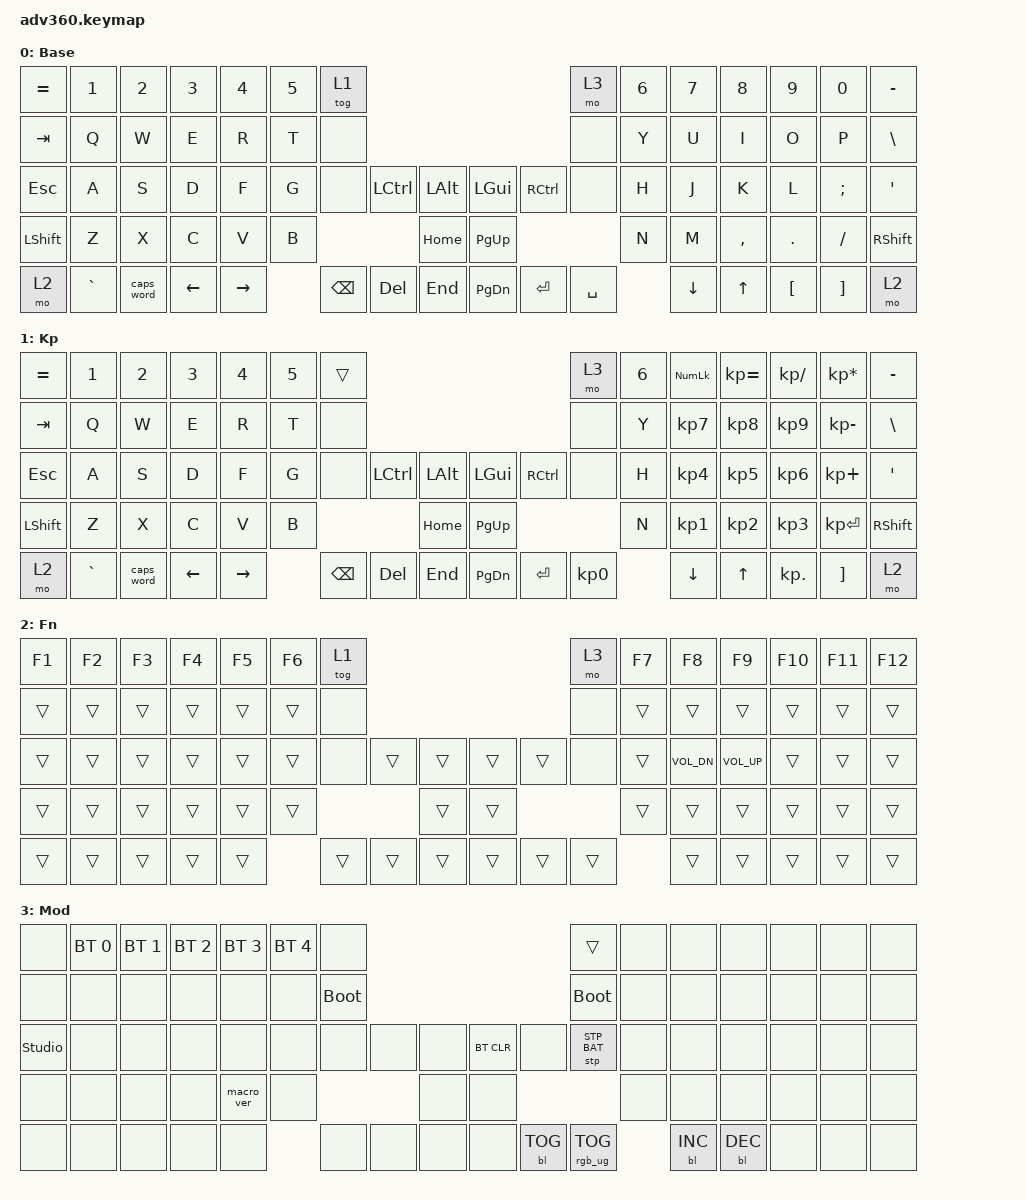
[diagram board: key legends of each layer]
/*
 * Copyright (c) 2020 The ZMK Contributors
 *
 * SPDX-License-Identifier: MIT
 *
 * THIS FILE WAS GENERATED!
 *
 * This file was generated automatically. You may or may not want to
 * edit it directly.
 */

#include <dt-bindings/zmk/stp.h>
#include <behaviors.dtsi>
#include <dt-bindings/zmk/backlight.h>
#include <dt-bindings/zmk/bt.h>
#include <dt-bindings/zmk/keys.h>
#include <dt-bindings/zmk/rgb.h>

#define P_Q 15
#define P_W 16
#define P_E 17
#define P_R 18
#define P_T 19
#define P_Y 22
#define P_U 23
#define P_I 24
#define P_O 25
#define P_P 26
#define P_A 29
#define P_S 30
#define P_D 31
#define P_F 32
#define P_G 33
#define P_H 40
#define P_J 41
#define P_K 42
#define P_L 43
#define P_SEMI 44
#define P_Z 47
#define P_X 48
#define P_C 49
#define P_V 50
#define P_B 51
#define P_N 54
#define P_M 55
#define P_COMA 56
#define P_DOT 57
#define P_SPC 70 // used as repeated letter key for chords
#define P_BSPC 65 // used as past tense key for chords
#define P_DELETE 66 // used as present tense key for chords

&caps_word {
};

/ {
    behaviors {
        #include "macros.dtsi"
        #include "version.dtsi"

        hm: homerow_mods {
            compatible = "zmk,behavior-hold-tap";
            label = "HOMEROW_MODS";
            #binding-cells = <2>;
            tapping-term-ms = <200>;
            quick_tap_ms = <175>;
            flavor = "tap-preferred";
            bindings = <&kp>, <&kp>;
        };
    };

    combos {
        compatible = "zmk,combos";
        // Below are auto generated
        // COMBOS START
    // about
    combo_m_abou {
      key-positions = <P_A P_B P_O P_U>;
      bindings = <&m_abou>;
    };
    // above
    combo_m_avbo {
      key-positions = <P_A P_V P_B P_O>;
      bindings = <&m_avbo>;
    };
    // add
    combo_m_ad {
      key-positions = <P_A P_D>;
      bindings = <&m_ad>;
    };
    // after
    combo_m_aef {
      key-positions = <P_A P_E P_F>;
      bindings = <&m_aef>;
    };
    // again
    combo_m_agin {
      key-positions = <P_A P_G P_I P_N>;
      bindings = <&m_agin>;
    };
    // air
    combo_m_air {
      key-positions = <P_A P_I P_R>;
      bindings = <&m_air>;
    };
    // all
    combo_m_al {
      key-positions = <P_A P_L>;
      bindings = <&m_al>;
    };
    // almost
    combo_m_aml {
      key-positions = <P_A P_M P_L>;
      bindings = <&m_aml>;
    };
    // along
    combo_m_agln {
      key-positions = <P_A P_G P_L P_N>;
      bindings = <&m_agln>;
    };
    // also
    combo_m_asl {
      key-positions = <P_A P_S P_L>;
      bindings = <&m_asl>;
    };
    // always
    combo_m_awly {
      key-positions = <P_A P_W P_L P_Y>;
      bindings = <&m_awly>;
    };
    // an
    combo_m_an {
      key-positions = <P_A P_N>;
      bindings = <&m_an>;
    };
    // and
    combo_m_and {
      key-positions = <P_A P_N P_D>;
      bindings = <&m_and>;
    };
    // animal
    combo_m_ani {
      key-positions = <P_A P_N P_I>;
      bindings = <&m_ani>;
    };
    // another
    combo_m_atno {
      key-positions = <P_A P_T P_N P_O>;
      bindings = <&m_atno>;
    };
    // answer
    combo_m_awern {
      key-positions = <P_A P_W P_E P_R P_N>;
      bindings = <&m_awern>;
    };
    // any
    combo_m_ay {
      key-positions = <P_A P_Y>;
      bindings = <&m_ay>;
    };
    // are
    combo_m_are {
      key-positions = <P_A P_R P_E>;
      bindings = <&m_are>;
    };
    // around
    combo_m_adrou {
      key-positions = <P_A P_D P_R P_O P_U>;
      bindings = <&m_adrou>;
    };
    // as
    combo_m_as {
      key-positions = <P_A P_S>;
      bindings = <&m_as>;
    };
    // ask
    combo_m_ask {
      key-positions = <P_A P_S P_K>;
      bindings = <&m_ask>;
    };
    // at
    combo_m_at {
      key-positions = <P_A P_T>;
      bindings = <&m_at>;
    };
    // ate
    combo_m_eatDELETE {
      key-positions = <P_E P_A P_T P_DELETE>;
      bindings = <&m_eatDELETE>;
    };
    // away
    combo_m_awaSPC {
      key-positions = <P_A P_W P_A P_SPC>;
      bindings = <&m_awaSPC>;
    };
    // back
    combo_m_acbk {
      key-positions = <P_A P_C P_B P_K>;
      bindings = <&m_acbk>;
    };
    // be
    combo_m_be {
      key-positions = <P_B P_E>;
      bindings = <&m_be>;
    };
    // become
    combo_m_bemoSPC {
      key-positions = <P_B P_E P_M P_O P_SPC>;
      bindings = <&m_bemoSPC>;
    };
    // because
    combo_m_bc {
      key-positions = <P_B P_C>;
      bindings = <&m_bc>;
    };
    // been
    combo_m_beSPCn {
      key-positions = <P_B P_E P_SPC P_N>;
      bindings = <&m_beSPCn>;
    };
    // before
    combo_m_bfoSPC {
      key-positions = <P_B P_F P_O P_SPC>;
      bindings = <&m_bfoSPC>;
    };
    // began
    combo_m_bgBSPC {
      key-positions = <P_B P_G P_BSPC>;
      bindings = <&m_bgBSPC>;
    };
    // begin
    combo_m_bg {
      key-positions = <P_B P_G>;
      bindings = <&m_bg>;
    };
    // being
    combo_m_beDELETE {
      key-positions = <P_B P_E P_DELETE>;
      bindings = <&m_beDELETE>;
    };
    // below
    combo_m_bel {
      key-positions = <P_B P_E P_L>;
      bindings = <&m_bel>;
    };
    // dev
    combo_m_dv {
      key-positions = <P_D P_V>;
      bindings = <&m_dv>;
    };
    // develop
    combo_m_dvlp {
      key-positions = <P_D P_V P_L P_P>;
      bindings = <&m_dvlp>;
    };
    // between
    combo_m_bew {
      key-positions = <P_B P_E P_W>;
      bindings = <&m_bew>;
    };
    // big
    combo_m_bi {
      key-positions = <P_B P_I>;
      bindings = <&m_bi>;
    };
    // book
    combo_m_boSPCk {
      key-positions = <P_B P_O P_SPC P_K>;
      bindings = <&m_boSPCk>;
    };
    // book
    combo_m_bok {
      key-positions = <P_B P_O P_K>;
      bindings = <&m_bok>;
    };
    // both
    combo_m_boh {
      key-positions = <P_B P_O P_H>;
      bindings = <&m_boh>;
    };
    // boy
    combo_m_boy {
      key-positions = <P_B P_O P_Y>;
      bindings = <&m_boy>;
    };
    // but
    combo_m_bu {
      key-positions = <P_B P_U>;
      bindings = <&m_bu>;
    };
    // by
    combo_m_by {
      key-positions = <P_B P_Y>;
      bindings = <&m_by>;
    };
    // call
    combo_m_cal {
      key-positions = <P_C P_A P_L>;
      bindings = <&m_cal>;
    };
    // came
    combo_m_cam {
      key-positions = <P_C P_A P_M>;
      bindings = <&m_cam>;
    };
    // can
    combo_m_can {
      key-positions = <P_C P_A P_N>;
      bindings = <&m_can>;
    };
    // car
    combo_m_car {
      key-positions = <P_C P_A P_R>;
      bindings = <&m_car>;
    };
    // carry
    combo_m_carSPCy {
      key-positions = <P_C P_A P_R P_SPC P_Y>;
      bindings = <&m_carSPCy>;
    };
    // carry
    combo_m_cary {
      key-positions = <P_C P_A P_R P_Y>;
      bindings = <&m_cary>;
    };
    // change
    combo_m_chag {
      key-positions = <P_C P_H P_A P_G>;
      bindings = <&m_chag>;
    };
    // children
    combo_m_chilr {
      key-positions = <P_C P_H P_I P_L P_R>;
      bindings = <&m_chilr>;
    };
    // city
    combo_m_city {
      key-positions = <P_C P_I P_T P_Y>;
      bindings = <&m_city>;
    };
    // close
    combo_m_cls {
      key-positions = <P_C P_L P_S>;
      bindings = <&m_cls>;
    };
    // come
    combo_m_com {
      key-positions = <P_C P_O P_M>;
      bindings = <&m_com>;
    };
    // consider
    combo_m_consir {
      key-positions = <P_C P_O P_N P_S P_I P_R>;
      bindings = <&m_consir>;
    };
    // could
    combo_m_cou {
      key-positions = <P_C P_O P_U>;
      bindings = <&m_cou>;
    };
    // course
    combo_m_cours {
      key-positions = <P_C P_O P_U P_R P_S>;
      bindings = <&m_cours>;
    };
    // country
    combo_m_cout {
      key-positions = <P_C P_O P_U P_T>;
      bindings = <&m_cout>;
    };
    // cut
    combo_m_cut {
      key-positions = <P_C P_U P_T>;
      bindings = <&m_cut>;
    };
    // day
    combo_m_day {
      key-positions = <P_D P_A P_Y>;
      bindings = <&m_day>;
    };
    // did
    combo_m_di {
      key-positions = <P_D P_I>;
      bindings = <&m_di>;
    };
    // did
    combo_m_diSPC {
      key-positions = <P_D P_I P_SPC>;
      bindings = <&m_diSPC>;
    };
    // different
    combo_m_difSPC {
      key-positions = <P_D P_I P_F P_SPC>;
      bindings = <&m_difSPC>;
    };
    // do
    combo_m_do {
      key-positions = <P_D P_O>;
      bindings = <&m_do>;
    };
    // does
    combo_m_dos {
      key-positions = <P_D P_O P_S>;
      bindings = <&m_dos>;
    };
    // don't
    combo_m_dont {
      key-positions = <P_D P_O P_N P_T>;
      bindings = <&m_dont>;
    };
    // down
    combo_m_down {
      key-positions = <P_D P_O P_W P_N>;
      bindings = <&m_down>;
    };
    // during
    combo_m_durDELETE {
      key-positions = <P_D P_U P_R P_DELETE>;
      bindings = <&m_durDELETE>;
    };
    // each
    combo_m_eah {
      key-positions = <P_E P_A P_H>;
      bindings = <&m_eah>;
    };
    // early
    combo_m_early {
      key-positions = <P_E P_A P_R P_L P_Y>;
      bindings = <&m_early>;
    };
    // earth
    combo_m_earSPCh {
      key-positions = <P_E P_A P_R P_SPC P_H>;
      bindings = <&m_earSPCh>;
    };
    // eat
    combo_m_eat {
      key-positions = <P_E P_A P_T>;
      bindings = <&m_eat>;
    };
    // end
    combo_m_en {
      key-positions = <P_E P_N>;
      bindings = <&m_en>;
    };
    // enough
    combo_m_enog {
      key-positions = <P_E P_N P_O P_G>;
      bindings = <&m_enog>;
    };
    // even
    combo_m_evSPCn {
      key-positions = <P_E P_V P_SPC P_N>;
      bindings = <&m_evSPCn>;
    };
    // even
    combo_m_evn {
      key-positions = <P_E P_V P_N>;
      bindings = <&m_evn>;
    };
    // every
    combo_m_SPCevy {
      key-positions = <P_SPC P_E P_V P_Y>;
      bindings = <&m_SPCevy>;
    };
    // example
    combo_m_ex {
      key-positions = <P_E P_X>;
      bindings = <&m_ex>;
    };
    // example
    combo_m_exampl {
      key-positions = <P_E P_X P_A P_M P_P P_L>;
      bindings = <&m_exampl>;
    };
    // eye
    combo_m_ey {
      key-positions = <P_E P_Y>;
      bindings = <&m_ey>;
    };
    // eye
    combo_m_eySPC {
      key-positions = <P_E P_Y P_SPC>;
      bindings = <&m_eySPC>;
    };
    // face
    combo_m_fac {
      key-positions = <P_F P_A P_C>;
      bindings = <&m_fac>;
    };
    // fact
    combo_m_facSPC {
      key-positions = <P_F P_A P_C P_SPC>;
      bindings = <&m_facSPC>;
    };
    // family
    combo_m_fam {
      key-positions = <P_F P_A P_M>;
      bindings = <&m_fam>;
    };
    // family
    combo_m_famil {
      key-positions = <P_F P_A P_M P_I P_L>;
      bindings = <&m_famil>;
    };
    // far
    combo_m_fa {
      key-positions = <P_F P_A>;
      bindings = <&m_fa>;
    };
    // father
    combo_m_fahe {
      key-positions = <P_F P_A P_H P_E>;
      bindings = <&m_fahe>;
    };
    // feet
    combo_m_feSPC {
      key-positions = <P_F P_E P_SPC>;
      bindings = <&m_feSPC>;
    };
    // feel
    combo_m_feSPCl {
      key-positions = <P_F P_E P_SPC P_L>;
      bindings = <&m_feSPCl>;
    };
    // fell
    combo_m_felBSPC {
      key-positions = <P_F P_E P_L P_BSPC>;
      bindings = <&m_felBSPC>;
    };
    // few
    combo_m_few {
      key-positions = <P_F P_E P_W>;
      bindings = <&m_few>;
    };
    // find
    combo_m_find {
      key-positions = <P_F P_I P_N P_D>;
      bindings = <&m_find>;
    };
    // first
    combo_m_fis {
      key-positions = <P_F P_I P_S>;
      bindings = <&m_fis>;
    };
    // follow
    combo_m_foSPCw {
      key-positions = <P_F P_O P_SPC P_W>;
      bindings = <&m_foSPCw>;
    };
    // food
    combo_m_foSPCd {
      key-positions = <P_F P_O P_SPC P_D>;
      bindings = <&m_foSPCd>;
    };
    // food
    combo_m_fod {
      key-positions = <P_F P_O P_D>;
      bindings = <&m_fod>;
    };
    // for
    combo_m_foBSPC {
      key-positions = <P_F P_O P_BSPC>;
      bindings = <&m_foBSPC>;
    };
    // form
    combo_m_fom {
      key-positions = <P_F P_O P_M>;
      bindings = <&m_fom>;
    };
    // found
    combo_m_foud {
      key-positions = <P_F P_O P_U P_D>;
      bindings = <&m_foud>;
    };
    // four
    combo_m_fouBSPC {
      key-positions = <P_F P_O P_U P_BSPC>;
      bindings = <&m_fouBSPC>;
    };
    // from
    combo_m_rom {
      key-positions = <P_R P_O P_M>;
      bindings = <&m_rom>;
    };
    // get
    combo_m_ge {
      key-positions = <P_G P_E>;
      bindings = <&m_ge>;
    };
    // general
    combo_m_genal {
      key-positions = <P_G P_E P_N P_A P_L>;
      bindings = <&m_genal>;
    };
    // girl
    combo_m_girl {
      key-positions = <P_G P_I P_R P_L>;
      bindings = <&m_girl>;
    };
    // girl
    combo_m_gil {
      key-positions = <P_G P_I P_L>;
      bindings = <&m_gil>;
    };
    // give
    combo_m_gie {
      key-positions = <P_G P_I P_E>;
      bindings = <&m_gie>;
    };
    // go
    combo_m_go {
      key-positions = <P_G P_O>;
      bindings = <&m_go>;
    };
    // good
    combo_m_goSPCd {
      key-positions = <P_G P_O P_SPC P_D>;
      bindings = <&m_goSPCd>;
    };
    // got
    combo_m_got {
      key-positions = <P_G P_O P_T>;
      bindings = <&m_got>;
    };
    // great
    combo_m_gea {
      key-positions = <P_G P_E P_A>;
      bindings = <&m_gea>;
    };
    // group
    combo_m_goup {
      key-positions = <P_G P_O P_U P_P>;
      bindings = <&m_goup>;
    };
    // grow
    combo_m_gow {
      key-positions = <P_G P_O P_W>;
      bindings = <&m_gow>;
    };
    // had
    combo_m_had {
      key-positions = <P_H P_A P_D>;
      bindings = <&m_had>;
    };
    // hand
    combo_m_haSPCd {
      key-positions = <P_H P_A P_SPC P_D>;
      bindings = <&m_haSPCd>;
    };
    // hard
    combo_m_hard {
      key-positions = <P_H P_A P_R P_D>;
      bindings = <&m_hard>;
    };
    // has
    combo_m_has {
      key-positions = <P_H P_A P_S>;
      bindings = <&m_has>;
    };
    // have
    combo_m_have {
      key-positions = <P_H P_A P_V P_E>;
      bindings = <&m_have>;
    };
    // he
    combo_m_he {
      key-positions = <P_H P_E>;
      bindings = <&m_he>;
    };
    // head
    combo_m_heaBSPC {
      key-positions = <P_H P_E P_A P_BSPC>;
      bindings = <&m_heaBSPC>;
    };
    // hear
    combo_m_hear {
      key-positions = <P_H P_E P_A P_R>;
      bindings = <&m_hear>;
    };
    // hello
    combo_m_hel {
      key-positions = <P_H P_E P_L>;
      bindings = <&m_hel>;
    };
    // help
    combo_m_help {
      key-positions = <P_H P_E P_L P_P>;
      bindings = <&m_help>;
    };
    // her
    combo_m_her {
      key-positions = <P_H P_E P_R>;
      bindings = <&m_her>;
    };
    // here
    combo_m_herSPC {
      key-positions = <P_H P_E P_R P_SPC>;
      bindings = <&m_herSPC>;
    };
    // high
    combo_m_hig {
      key-positions = <P_H P_I P_G>;
      bindings = <&m_hig>;
    };
    // him
    combo_m_hi {
      key-positions = <P_H P_I>;
      bindings = <&m_hi>;
    };
    // his
    combo_m_his {
      key-positions = <P_H P_I P_S>;
      bindings = <&m_his>;
    };
    // home
    combo_m_hoe {
      key-positions = <P_H P_O P_E>;
      bindings = <&m_hoe>;
    };
    // hold
    combo_m_hod {
      key-positions = <P_H P_O P_D>;
      bindings = <&m_hod>;
    };
    // house
    combo_m_house {
      key-positions = <P_H P_O P_U P_S P_E>;
      bindings = <&m_house>;
    };
    // how
    combo_m_how {
      key-positions = <P_H P_O P_W>;
      bindings = <&m_how>;
    };
    // however
    combo_m_howev {
      key-positions = <P_H P_O P_W P_E P_V>;
      bindings = <&m_howev>;
    };
    // idea
    combo_m_ida {
      key-positions = <P_I P_D P_A>;
      bindings = <&m_ida>;
    };
    // if
    combo_m_if {
      key-positions = <P_I P_F>;
      bindings = <&m_if>;
    };
    // important
    combo_m_imp {
      key-positions = <P_I P_M P_P>;
      bindings = <&m_imp>;
    };
    // in
    combo_m_in {
      key-positions = <P_I P_N>;
      bindings = <&m_in>;
    };
    // increase
    combo_m_incr {
      key-positions = <P_I P_N P_C P_R>;
      bindings = <&m_incr>;
    };
    // interest
    combo_m_intes {
      key-positions = <P_I P_N P_T P_E P_S>;
      bindings = <&m_intes>;
    };
    // into
    combo_m_into {
      key-positions = <P_I P_N P_T P_O>;
      bindings = <&m_into>;
    };
    // is
    combo_m_is {
      key-positions = <P_I P_S>;
      bindings = <&m_is>;
    };
    // it
    combo_m_it {
      key-positions = <P_I P_T>;
      bindings = <&m_it>;
    };
    // it's
    combo_m_itsBSPC {
      key-positions = <P_I P_T P_S P_BSPC>;
      bindings = <&m_itsBSPC>;
    };
    // it_is
    combo_m_itsDELETE {
      key-positions = <P_I P_T P_S P_DELETE>;
      bindings = <&m_itsDELETE>;
    };
    // its
    combo_m_its {
      key-positions = <P_I P_T P_S>;
      bindings = <&m_its>;
    };
    // just
    combo_m_jst {
      key-positions = <P_J P_S P_T>;
      bindings = <&m_jst>;
    };
    // keep
    combo_m_keSPCp {
      key-positions = <P_K P_E P_SPC P_P>;
      bindings = <&m_keSPCp>;
    };
    // keeping
    combo_m_keSPCpDELETE {
      key-positions = <P_K P_E P_SPC P_P P_DELETE>;
      bindings = <&m_keSPCpDELETE>;
    };
    // kind
    combo_m_knd {
      key-positions = <P_K P_N P_D>;
      bindings = <&m_knd>;
    };
    // know
    combo_m_know {
      key-positions = <P_K P_N P_O P_W>;
      bindings = <&m_know>;
    };
    // knowing
    combo_m_knowDELETE {
      key-positions = <P_K P_N P_O P_W P_DELETE>;
      bindings = <&m_knowDELETE>;
    };
    // land
    combo_m_land {
      key-positions = <P_L P_A P_N P_D>;
      bindings = <&m_land>;
    };
    // landing
    combo_m_landDELETE {
      key-positions = <P_L P_A P_N P_D P_DELETE>;
      bindings = <&m_landDELETE>;
    };
    // large
    combo_m_larg {
      key-positions = <P_L P_A P_R P_G>;
      bindings = <&m_larg>;
    };
    // last
    combo_m_last {
      key-positions = <P_L P_A P_S P_T>;
      bindings = <&m_last>;
    };
    // late
    combo_m_late {
      key-positions = <P_L P_A P_T P_E>;
      bindings = <&m_late>;
    };
    // later
    combo_m_lateBSPC {
      key-positions = <P_L P_A P_T P_E P_BSPC>;
      bindings = <&m_lateBSPC>;
    };
    // lead
    combo_m_lea {
      key-positions = <P_L P_E P_A>;
      bindings = <&m_lea>;
    };
    // learn
    combo_m_learn {
      key-positions = <P_L P_E P_A P_R P_N>;
      bindings = <&m_learn>;
    };
    // learning
    combo_m_learnDELETE {
      key-positions = <P_L P_E P_A P_R P_N P_DELETE>;
      bindings = <&m_learnDELETE>;
    };
    // leave
    combo_m_leavSPC {
      key-positions = <P_L P_E P_A P_V P_SPC>;
      bindings = <&m_leavSPC>;
    };
    // leaving
    combo_m_leavDELETE {
      key-positions = <P_L P_E P_A P_V P_DELETE>;
      bindings = <&m_leavDELETE>;
    };
    // left
    combo_m_lef {
      key-positions = <P_L P_E P_F>;
      bindings = <&m_lef>;
    };
    // let
    combo_m_let {
      key-positions = <P_L P_E P_T>;
      bindings = <&m_let>;
    };
    // letter
    combo_m_lter {
      key-positions = <P_L P_T P_E P_R>;
      bindings = <&m_lter>;
    };
    // text
    combo_m_tex {
      key-positions = <P_T P_E P_X>;
      bindings = <&m_tex>;
    };
    // texting
    combo_m_texDELETE {
      key-positions = <P_T P_E P_X P_DELETE>;
      bindings = <&m_texDELETE>;
    };
    // life
    combo_m_life {
      key-positions = <P_L P_I P_F P_E>;
      bindings = <&m_life>;
    };
    // light
    combo_m_ligh {
      key-positions = <P_L P_I P_G P_H>;
      bindings = <&m_ligh>;
    };
    // like
    combo_m_lie {
      key-positions = <P_L P_I P_E>;
      bindings = <&m_lie>;
    };
    // line
    combo_m_line {
      key-positions = <P_L P_I P_N P_E>;
      bindings = <&m_line>;
    };
    // list
    combo_m_list {
      key-positions = <P_L P_I P_S P_T>;
      bindings = <&m_list>;
    };
    // little
    combo_m_lite {
      key-positions = <P_L P_I P_T P_E>;
      bindings = <&m_lite>;
    };
    // live
    combo_m_live {
      key-positions = <P_L P_I P_V P_E>;
      bindings = <&m_live>;
    };
    // long
    combo_m_lng {
      key-positions = <P_L P_N P_G>;
      bindings = <&m_lng>;
    };
    // look
    combo_m_lSPCk {
      key-positions = <P_L P_SPC P_K>;
      bindings = <&m_lSPCk>;
    };
    // made
    combo_m_madSPC {
      key-positions = <P_M P_A P_D P_SPC>;
      bindings = <&m_madSPC>;
    };
    // make
    combo_m_make {
      key-positions = <P_M P_A P_K P_E>;
      bindings = <&m_make>;
    };
    // man
    combo_m_man {
      key-positions = <P_M P_A P_N>;
      bindings = <&m_man>;
    };
    // many
    combo_m_manDELETE {
      key-positions = <P_M P_A P_N P_DELETE>;
      bindings = <&m_manDELETE>;
    };
    // may
    combo_m_mae {
      key-positions = <P_M P_A P_E>;
      bindings = <&m_mae>;
    };
    // me
    combo_m_me {
      key-positions = <P_M P_E>;
      bindings = <&m_me>;
    };
    // mean
    combo_m_mean {
      key-positions = <P_M P_E P_A P_N>;
      bindings = <&m_mean>;
    };
    // men
    combo_m_men {
      key-positions = <P_M P_E P_N>;
      bindings = <&m_men>;
    };
    // might
    combo_m_mig {
      key-positions = <P_M P_I P_G>;
      bindings = <&m_mig>;
    };
    // mile
    combo_m_mile {
      key-positions = <P_M P_I P_L P_E>;
      bindings = <&m_mile>;
    };
    // miss
    combo_m_misSPC {
      key-positions = <P_M P_I P_S P_SPC>;
      bindings = <&m_misSPC>;
    };
    // more
    combo_m_more {
      key-positions = <P_M P_O P_R P_E>;
      bindings = <&m_more>;
    };
    // most
    combo_m_most {
      key-positions = <P_M P_O P_S P_T>;
      bindings = <&m_most>;
    };
    // mother
    combo_m_mote {
      key-positions = <P_M P_O P_T P_E>;
      bindings = <&m_mote>;
    };
    // mountain
    combo_m_motaSPCDELETE {
      key-positions = <P_M P_O P_T P_A P_SPC P_DELETE>;
      bindings = <&m_motaSPCDELETE>;
    };
    // move
    combo_m_move {
      key-positions = <P_M P_O P_V P_E>;
      bindings = <&m_move>;
    };
    // much
    combo_m_mc {
      key-positions = <P_M P_C>;
      bindings = <&m_mc>;
    };
    // must
    combo_m_mst {
      key-positions = <P_M P_S P_T>;
      bindings = <&m_mst>;
    };
    // my
    combo_m_mDELETE {
      key-positions = <P_M P_DELETE>;
      bindings = <&m_mDELETE>;
    };
    // name
    combo_m_nae {
      key-positions = <P_N P_A P_E>;
      bindings = <&m_nae>;
    };
    // nation
    combo_m_natio {
      key-positions = <P_N P_A P_T P_I P_O>;
      bindings = <&m_natio>;
    };
    // near
    combo_m_near {
      key-positions = <P_N P_E P_A P_R>;
      bindings = <&m_near>;
    };
    // need
    combo_m_neSPC {
      key-positions = <P_N P_E P_SPC>;
      bindings = <&m_neSPC>;
    };
    // never
    combo_m_nevBSPC {
      key-positions = <P_N P_E P_V P_BSPC>;
      bindings = <&m_nevBSPC>;
    };
    // new
    combo_m_new {
      key-positions = <P_N P_E P_W>;
      bindings = <&m_new>;
    };
    // next
    combo_m_next {
      key-positions = <P_N P_E P_X P_T>;
      bindings = <&m_next>;
    };
    // night
    combo_m_nig {
      key-positions = <P_N P_I P_G>;
      bindings = <&m_nig>;
    };
    // no
    combo_m_nSPC {
      key-positions = <P_N P_SPC>;
      bindings = <&m_nSPC>;
    };
    // not
    combo_m_not {
      key-positions = <P_N P_O P_T>;
      bindings = <&m_not>;
    };
    // now
    combo_m_nSPCw {
      key-positions = <P_N P_SPC P_W>;
      bindings = <&m_nSPCw>;
    };
    // number
    combo_m_nmb {
      key-positions = <P_N P_M P_B>;
      bindings = <&m_nmb>;
    };
    // off
    combo_m_ofSPC {
      key-positions = <P_O P_F P_SPC>;
      bindings = <&m_ofSPC>;
    };
    // of
    combo_m_of {
      key-positions = <P_O P_F>;
      bindings = <&m_of>;
    };
    // often
    combo_m_ofe {
      key-positions = <P_O P_F P_E>;
      bindings = <&m_ofe>;
    };
    // old
    combo_m_oSPCd {
      key-positions = <P_O P_SPC P_D>;
      bindings = <&m_oSPCd>;
    };
    // on
    combo_m_on {
      key-positions = <P_O P_N>;
      bindings = <&m_on>;
    };
    // once
    combo_m_onc {
      key-positions = <P_O P_N P_C>;
      bindings = <&m_onc>;
    };
    // one
    combo_m_one {
      key-positions = <P_O P_N P_E>;
      bindings = <&m_one>;
    };
    // only
    combo_m_onDELETE {
      key-positions = <P_O P_N P_DELETE>;
      bindings = <&m_onDELETE>;
    };
    // open
    combo_m_open {
      key-positions = <P_O P_P P_E P_N>;
      bindings = <&m_open>;
    };
    // or
    combo_m_or {
      key-positions = <P_O P_R>;
      bindings = <&m_or>;
    };
    // order
    combo_m_ordSPC {
      key-positions = <P_O P_R P_D P_SPC>;
      bindings = <&m_ordSPC>;
    };
    // other
    combo_m_othe {
      key-positions = <P_O P_T P_H P_E>;
      bindings = <&m_othe>;
    };
    // our
    combo_m_our {
      key-positions = <P_O P_U P_R>;
      bindings = <&m_our>;
    };
    // out
    combo_m_out {
      key-positions = <P_O P_U P_T>;
      bindings = <&m_out>;
    };
    // over
    combo_m_ove {
      key-positions = <P_O P_V P_E>;
      bindings = <&m_ove>;
    };
    // own
    combo_m_own {
      key-positions = <P_O P_W P_N>;
      bindings = <&m_own>;
    };
    // page
    combo_m_page {
      key-positions = <P_P P_A P_G P_E>;
      bindings = <&m_page>;
    };
    // paper
    combo_m_paer {
      key-positions = <P_P P_A P_E P_R>;
      bindings = <&m_paer>;
    };
    // part
    combo_m_par {
      key-positions = <P_P P_A P_R>;
      bindings = <&m_par>;
    };
    // people
    combo_m_peoSPC {
      key-positions = <P_P P_E P_O P_SPC>;
      bindings = <&m_peoSPC>;
    };
    // person
    combo_m_pers {
      key-positions = <P_P P_E P_R P_S>;
      bindings = <&m_pers>;
    };
    // picture
    combo_m_pict {
      key-positions = <P_P P_I P_C P_T>;
      bindings = <&m_pict>;
    };
    // place
    combo_m_plac {
      key-positions = <P_P P_L P_A P_C>;
      bindings = <&m_plac>;
    };
    // plant
    combo_m_plan {
      key-positions = <P_P P_L P_A P_N>;
      bindings = <&m_plan>;
    };
    // plant
    combo_m_plant {
      key-positions = <P_P P_L P_A P_N P_T>;
      bindings = <&m_plant>;
    };
    // play
    combo_m_play {
      key-positions = <P_P P_L P_A P_Y>;
      bindings = <&m_play>;
    };
    // problem
    combo_m_proem {
      key-positions = <P_P P_R P_O P_E P_M>;
      bindings = <&m_proem>;
    };
    // program
    combo_m_proam {
      key-positions = <P_P P_R P_O P_A P_M>;
      bindings = <&m_proam>;
    };
    // present
    combo_m_presn {
      key-positions = <P_P P_R P_E P_S P_N>;
      bindings = <&m_presn>;
    };
    // point
    combo_m_point {
      key-positions = <P_P P_O P_I P_N P_T>;
      bindings = <&m_point>;
    };
    // position
    combo_m_pos {
      key-positions = <P_P P_O P_S>;
      bindings = <&m_pos>;
    };
    // possible
    combo_m_posib {
      key-positions = <P_P P_O P_S P_I P_B>;
      bindings = <&m_posib>;
    };
    // put
    combo_m_put {
      key-positions = <P_P P_U P_T>;
      bindings = <&m_put>;
    };
    // public
    combo_m_pubic {
      key-positions = <P_P P_U P_B P_I P_C>;
      bindings = <&m_pubic>;
    };
    // question
    combo_m_quet {
      key-positions = <P_Q P_U P_E P_T>;
      bindings = <&m_quet>;
    };
    // quick
    combo_m_qui {
      key-positions = <P_Q P_U P_I>;
      bindings = <&m_qui>;
    };
    // quickly
    combo_m_quiDELETE {
      key-positions = <P_Q P_U P_I P_DELETE>;
      bindings = <&m_quiDELETE>;
    };
    // quite
    combo_m_quite {
      key-positions = <P_Q P_U P_I P_T P_E>;
      bindings = <&m_quite>;
    };
    // read
    combo_m_reaBSPC {
      key-positions = <P_R P_E P_A P_BSPC>;
      bindings = <&m_reaBSPC>;
    };
    // real
    combo_m_real {
      key-positions = <P_R P_E P_A P_L>;
      bindings = <&m_real>;
    };
    // really
    combo_m_realDELETE {
      key-positions = <P_R P_E P_A P_L P_DELETE>;
      bindings = <&m_realDELETE>;
    };
    // right
    combo_m_righ {
      key-positions = <P_R P_I P_G P_H>;
      bindings = <&m_righ>;
    };
    // river
    combo_m_rie {
      key-positions = <P_R P_I P_E>;
      bindings = <&m_rie>;
    };
    // run
    combo_m_ru {
      key-positions = <P_R P_U>;
      bindings = <&m_ru>;
    };
    // said
    combo_m_said {
      key-positions = <P_S P_A P_I P_D>;
      bindings = <&m_said>;
    };
    // same
    combo_m_same {
      key-positions = <P_S P_A P_M P_E>;
      bindings = <&m_same>;
    };
    // saw
    combo_m_saBSPC {
      key-positions = <P_S P_A P_BSPC>;
      bindings = <&m_saBSPC>;
    };
    // say
    combo_m_say {
      key-positions = <P_S P_A P_Y>;
      bindings = <&m_say>;
    };
    // school
    combo_m_scho {
      key-positions = <P_S P_C P_H P_O>;
      bindings = <&m_scho>;
    };
    // sea
    combo_m_sea {
      key-positions = <P_S P_E P_A>;
      bindings = <&m_sea>;
    };
    // second
    combo_m_seon {
      key-positions = <P_S P_E P_O P_N>;
      bindings = <&m_seon>;
    };
    // see
    combo_m_seSPC {
      key-positions = <P_S P_E P_SPC>;
      bindings = <&m_seSPC>;
    };
    // seem
    combo_m_seSPCm {
      key-positions = <P_S P_E P_SPC P_M>;
      bindings = <&m_seSPCm>;
    };
    // sentence
    combo_m_sent {
      key-positions = <P_S P_E P_N P_T>;
      bindings = <&m_sent>;
    };
    // set
    combo_m_set {
      key-positions = <P_S P_E P_T>;
      bindings = <&m_set>;
    };
    // she
    combo_m_she {
      key-positions = <P_S P_H P_E>;
      bindings = <&m_she>;
    };
    // should
    combo_m_shoSPCd {
      key-positions = <P_S P_H P_O P_SPC P_D>;
      bindings = <&m_shoSPCd>;
    };
    // show
    combo_m_sho {
      key-positions = <P_S P_H P_O>;
      bindings = <&m_sho>;
    };
    // side
    combo_m_sid {
      key-positions = <P_S P_I P_D>;
      bindings = <&m_sid>;
    };
    // since
    combo_m_sinc {
      key-positions = <P_S P_I P_N P_C>;
      bindings = <&m_sinc>;
    };
    // small
    combo_m_smal {
      key-positions = <P_S P_M P_A P_L>;
      bindings = <&m_smal>;
    };
    // so
    combo_m_so {
      key-positions = <P_S P_O>;
      bindings = <&m_so>;
    };
    // some
    combo_m_some {
      key-positions = <P_S P_O P_M P_E>;
      bindings = <&m_some>;
    };
    // something
    combo_m_somet {
      key-positions = <P_S P_O P_M P_E P_T>;
      bindings = <&m_somet>;
    };
    // sometimes
    combo_m_sometSPC {
      key-positions = <P_S P_O P_M P_E P_T P_SPC>;
      bindings = <&m_sometSPC>;
    };
    // song
    combo_m_song {
      key-positions = <P_S P_O P_N P_G>;
      bindings = <&m_song>;
    };
    // soon
    combo_m_soSPCn {
      key-positions = <P_S P_O P_SPC P_N>;
      bindings = <&m_soSPCn>;
    };
    // sound
    combo_m_soud {
      key-positions = <P_S P_O P_U P_D>;
      bindings = <&m_soud>;
    };
    // spell
    combo_m_spel {
      key-positions = <P_S P_P P_E P_L>;
      bindings = <&m_spel>;
    };
    // speed
    combo_m_speSPC {
      key-positions = <P_S P_P P_E P_SPC>;
      bindings = <&m_speSPC>;
    };
    // start
    combo_m_star {
      key-positions = <P_S P_T P_A P_R>;
      bindings = <&m_star>;
    };
    // state
    combo_m_stae {
      key-positions = <P_S P_T P_A P_E>;
      bindings = <&m_stae>;
    };
    // still
    combo_m_stilSPC {
      key-positions = <P_S P_T P_I P_L P_SPC>;
      bindings = <&m_stilSPC>;
    };
    // stop
    combo_m_stop {
      key-positions = <P_S P_T P_O P_P>;
      bindings = <&m_stop>;
    };
    // story
    combo_m_stoy {
      key-positions = <P_S P_T P_O P_Y>;
      bindings = <&m_stoy>;
    };
    // study
    combo_m_stud {
      key-positions = <P_S P_T P_U P_D>;
      bindings = <&m_stud>;
    };
    // such
    combo_m_suc {
      key-positions = <P_S P_U P_C>;
      bindings = <&m_suc>;
    };
    // system
    combo_m_syte {
      key-positions = <P_S P_Y P_T P_E>;
      bindings = <&m_syte>;
    };
    // take
    combo_m_take {
      key-positions = <P_T P_A P_K P_E>;
      bindings = <&m_take>;
    };
    // talk
    combo_m_talk {
      key-positions = <P_T P_A P_L P_K>;
      bindings = <&m_talk>;
    };
    // tell
    combo_m_telSPC {
      key-positions = <P_T P_E P_L P_SPC>;
      bindings = <&m_telSPC>;
    };
    // than
    combo_m_thaDELETE {
      key-positions = <P_T P_H P_A P_DELETE>;
      bindings = <&m_thaDELETE>;
    };
    // that
    combo_m_tha {
      key-positions = <P_T P_H P_A>;
      bindings = <&m_tha>;
    };
    // their
    combo_m_thei {
      key-positions = <P_T P_H P_E P_I>;
      bindings = <&m_thei>;
    };
    // them
    combo_m_the {
      key-positions = <P_T P_H P_E>;
      bindings = <&m_the>;
    };
    // then
    combo_m_theBSPC {
      key-positions = <P_T P_H P_E P_BSPC>;
      bindings = <&m_theBSPC>;
    };
    // there
    combo_m_ther {
      key-positions = <P_T P_H P_E P_R>;
      bindings = <&m_ther>;
    };
    // these
    combo_m_thes {
      key-positions = <P_T P_H P_E P_S>;
      bindings = <&m_thes>;
    };
    // the
    combo_m_th {
      key-positions = <P_T P_H>;
      bindings = <&m_th>;
    };
    // they
    combo_m_theSPC {
      key-positions = <P_T P_H P_E P_SPC>;
      bindings = <&m_theSPC>;
    };
    // thing
    combo_m_thiDELETE {
      key-positions = <P_T P_H P_I P_DELETE>;
      bindings = <&m_thiDELETE>;
    };
    // think
    combo_m_thi {
      key-positions = <P_T P_H P_I>;
      bindings = <&m_thi>;
    };
    // this
    combo_m_this {
      key-positions = <P_T P_H P_I P_S>;
      bindings = <&m_this>;
    };
    // those
    combo_m_those {
      key-positions = <P_T P_H P_O P_S P_E>;
      bindings = <&m_those>;
    };
    // thought
    combo_m_touBSPC {
      key-positions = <P_T P_O P_U P_BSPC>;
      bindings = <&m_touBSPC>;
    };
    // three
    combo_m_threSPC {
      key-positions = <P_T P_H P_R P_E P_SPC>;
      bindings = <&m_threSPC>;
    };
    // through
    combo_m_thro {
      key-positions = <P_T P_H P_R P_O>;
      bindings = <&m_thro>;
    };
    // time
    combo_m_time {
      key-positions = <P_T P_I P_M P_E>;
      bindings = <&m_time>;
    };
    // type
    combo_m_type {
      key-positions = <P_T P_Y P_P P_E>;
      bindings = <&m_type>;
    };
    // typed
    combo_m_typeBSPC {
      key-positions = <P_T P_Y P_P P_E P_BSPC>;
      bindings = <&m_typeBSPC>;
    };
    // typing
    combo_m_typeDELETE {
      key-positions = <P_T P_Y P_P P_E P_DELETE>;
      bindings = <&m_typeDELETE>;
    };
    // together
    combo_m_toehSPC {
      key-positions = <P_T P_O P_E P_H P_SPC>;
      bindings = <&m_toehSPC>;
    };
    // too
    combo_m_toSPC {
      key-positions = <P_T P_O P_SPC>;
      bindings = <&m_toSPC>;
    };
    // took
    combo_m_toSPCk {
      key-positions = <P_T P_O P_SPC P_K>;
      bindings = <&m_toSPCk>;
    };
    // to
    combo_m_to {
      key-positions = <P_T P_O>;
      bindings = <&m_to>;
    };
    // tree
    combo_m_tre {
      key-positions = <P_T P_R P_E>;
      bindings = <&m_tre>;
    };
    // try
    combo_m_try {
      key-positions = <P_T P_R P_Y>;
      bindings = <&m_try>;
    };
    // turn
    combo_m_tur {
      key-positions = <P_T P_U P_R>;
      bindings = <&m_tur>;
    };
    // two
    combo_m_two {
      key-positions = <P_T P_W P_O>;
      bindings = <&m_two>;
    };
    // under
    combo_m_undr {
      key-positions = <P_U P_N P_D P_R>;
      bindings = <&m_undr>;
    };
    // until
    combo_m_uSPCtil {
      key-positions = <P_U P_SPC P_T P_I P_L>;
      bindings = <&m_uSPCtil>;
    };
    // up
    combo_m_up {
      key-positions = <P_U P_P>;
      bindings = <&m_up>;
    };
    // us
    combo_m_us {
      key-positions = <P_U P_S>;
      bindings = <&m_us>;
    };
    // use
    combo_m_use {
      key-positions = <P_U P_S P_E>;
      bindings = <&m_use>;
    };
    // very
    combo_m_vey {
      key-positions = <P_V P_E P_Y>;
      bindings = <&m_vey>;
    };
    // walk
    combo_m_walk {
      key-positions = <P_W P_A P_L P_K>;
      bindings = <&m_walk>;
    };
    // want
    combo_m_want {
      key-positions = <P_W P_A P_N P_T>;
      bindings = <&m_want>;
    };
    // was
    combo_m_waBSPC {
      key-positions = <P_W P_A P_BSPC>;
      bindings = <&m_waBSPC>;
    };
    // watch
    combo_m_waBSPCth {
      key-positions = <P_W P_A P_BSPC P_T P_H>;
      bindings = <&m_waBSPCth>;
    };
    // water
    combo_m_wate {
      key-positions = <P_W P_A P_T P_E>;
      bindings = <&m_wate>;
    };
    // way
    combo_m_way {
      key-positions = <P_W P_A P_Y>;
      bindings = <&m_way>;
    };
    // we
    combo_m_we {
      key-positions = <P_W P_E>;
      bindings = <&m_we>;
    };
    // well
    combo_m_wel {
      key-positions = <P_W P_E P_L>;
      bindings = <&m_wel>;
    };
    // went
    combo_m_went {
      key-positions = <P_W P_E P_N P_T>;
      bindings = <&m_went>;
    };
    // were
    combo_m_werSPC {
      key-positions = <P_W P_E P_R P_SPC>;
      bindings = <&m_werSPC>;
    };
    // what
    combo_m_what {
      key-positions = <P_W P_H P_A P_T>;
      bindings = <&m_what>;
    };
    // when
    combo_m_wheSPC {
      key-positions = <P_W P_H P_E P_SPC>;
      bindings = <&m_wheSPC>;
    };
    // where
    combo_m_wherSPC {
      key-positions = <P_W P_H P_E P_R P_SPC>;
      bindings = <&m_wherSPC>;
    };
    // which
    combo_m_whic {
      key-positions = <P_W P_H P_I P_C>;
      bindings = <&m_whic>;
    };
    // while
    combo_m_while {
      key-positions = <P_W P_H P_I P_L P_E>;
      bindings = <&m_while>;
    };
    // white
    combo_m_white {
      key-positions = <P_W P_H P_I P_T P_E>;
      bindings = <&m_white>;
    };
    // who
    combo_m_whoBSPC {
      key-positions = <P_W P_H P_O P_BSPC>;
      bindings = <&m_whoBSPC>;
    };
    // why
    combo_m_whDELETE {
      key-positions = <P_W P_H P_DELETE>;
      bindings = <&m_whDELETE>;
    };
    // will
    combo_m_wil {
      key-positions = <P_W P_I P_L>;
      bindings = <&m_wil>;
    };
    // with
    combo_m_with {
      key-positions = <P_W P_I P_T P_H>;
      bindings = <&m_with>;
    };
    // without
    combo_m_witho {
      key-positions = <P_W P_I P_T P_H P_O>;
      bindings = <&m_witho>;
    };
    // word
    combo_m_word {
      key-positions = <P_W P_O P_R P_D>;
      bindings = <&m_word>;
    };
    // work
    combo_m_work {
      key-positions = <P_W P_O P_R P_K>;
      bindings = <&m_work>;
    };
    // world
    combo_m_worSPCd {
      key-positions = <P_W P_O P_R P_SPC P_D>;
      bindings = <&m_worSPCd>;
    };
    // would
    combo_m_woud {
      key-positions = <P_W P_O P_U P_D>;
      bindings = <&m_woud>;
    };
    // write
    combo_m_wrie {
      key-positions = <P_W P_R P_I P_E>;
      bindings = <&m_wrie>;
    };
    // year
    combo_m_year {
      key-positions = <P_Y P_E P_A P_R>;
      bindings = <&m_year>;
    };
    // you
    combo_m_you {
      key-positions = <P_Y P_O P_U>;
      bindings = <&m_you>;
    };
    // young
    combo_m_youg {
      key-positions = <P_Y P_O P_U P_G>;
      bindings = <&m_youg>;
    };
    // your
    combo_m_your {
      key-positions = <P_Y P_O P_U P_R>;
      bindings = <&m_your>;
    };

        // COMBOS END
    };

    macros {
        // Below are auto generated
        // MACROS START
    // about
    ZMK_MACRO(m_abou,
        bindings = <&kp A &kp B &kp O &kp U &kp T &kp SPACE>;
    )
    // above
    ZMK_MACRO(m_avbo,
        bindings = <&kp A &kp B &kp O &kp V &kp E &kp SPACE>;
    )
    // add
    ZMK_MACRO(m_ad,
        bindings = <&kp A &kp D &kp D &kp SPACE>;
    )
    // after
    ZMK_MACRO(m_aef,
        bindings = <&kp A &kp F &kp T &kp E &kp R &kp SPACE>;
    )
    // again
    ZMK_MACRO(m_agin,
        bindings = <&kp A &kp G &kp A &kp I &kp N &kp SPACE>;
    )
    // air
    ZMK_MACRO(m_air,
        bindings = <&kp A &kp I &kp R &kp SPACE>;
    )
    // all
    ZMK_MACRO(m_al,
        bindings = <&kp A &kp L &kp L &kp SPACE>;
    )
    // almost
    ZMK_MACRO(m_aml,
        bindings = <&kp A &kp L &kp M &kp O &kp S &kp T &kp SPACE>;
    )
    // along
    ZMK_MACRO(m_agln,
        bindings = <&kp A &kp L &kp O &kp N &kp G &kp SPACE>;
    )
    // also
    ZMK_MACRO(m_asl,
        bindings = <&kp A &kp L &kp S &kp O &kp SPACE>;
    )
    // always
    ZMK_MACRO(m_awly,
        bindings = <&kp A &kp L &kp W &kp A &kp Y &kp S &kp SPACE>;
    )
    // an
    ZMK_MACRO(m_an,
        bindings = <&kp A &kp N &kp SPACE>;
    )
    // and
    ZMK_MACRO(m_and,
        bindings = <&kp A &kp N &kp D &kp SPACE>;
    )
    // animal
    ZMK_MACRO(m_ani,
        bindings = <&kp A &kp N &kp I &kp M &kp A &kp L &kp SPACE>;
    )
    // another
    ZMK_MACRO(m_atno,
        bindings = <&kp A &kp N &kp O &kp T &kp H &kp E &kp R &kp SPACE>;
    )
    // answer
    ZMK_MACRO(m_awern,
        bindings = <&kp A &kp N &kp S &kp W &kp E &kp R &kp SPACE>;
    )
    // any
    ZMK_MACRO(m_ay,
        bindings = <&kp A &kp N &kp Y &kp SPACE>;
    )
    // are
    ZMK_MACRO(m_are,
        bindings = <&kp A &kp R &kp E &kp SPACE>;
    )
    // around
    ZMK_MACRO(m_adrou,
        bindings = <&kp A &kp R &kp O &kp U &kp N &kp D &kp SPACE>;
    )
    // as
    ZMK_MACRO(m_as,
        bindings = <&kp A &kp S &kp SPACE>;
    )
    // ask
    ZMK_MACRO(m_ask,
        bindings = <&kp A &kp S &kp K &kp SPACE>;
    )
    // at
    ZMK_MACRO(m_at,
        bindings = <&kp A &kp T &kp SPACE>;
    )
    // ate
    ZMK_MACRO(m_eatDELETE,
        bindings = <&kp A &kp T &kp E &kp SPACE>;
    )
    // away
    ZMK_MACRO(m_awaSPC,
        bindings = <&kp A &kp W &kp A &kp Y &kp SPACE>;
    )
    // back
    ZMK_MACRO(m_acbk,
        bindings = <&kp B &kp A &kp C &kp K &kp SPACE>;
    )
    // be
    ZMK_MACRO(m_be,
        bindings = <&kp B &kp E &kp SPACE>;
    )
    // become
    ZMK_MACRO(m_bemoSPC,
        bindings = <&kp B &kp E &kp C &kp O &kp M &kp E &kp SPACE>;
    )
    // because
    ZMK_MACRO(m_bc,
        bindings = <&kp B &kp E &kp C &kp A &kp U &kp S &kp E &kp SPACE>;
    )
    // been
    ZMK_MACRO(m_beSPCn,
        bindings = <&kp B &kp E &kp E &kp N &kp SPACE>;
    )
    // before
    ZMK_MACRO(m_bfoSPC,
        bindings = <&kp B &kp E &kp F &kp O &kp R &kp E &kp SPACE>;
    )
    // began
    ZMK_MACRO(m_bgBSPC,
        bindings = <&kp B &kp E &kp G &kp A &kp N &kp SPACE>;
    )
    // begin
    ZMK_MACRO(m_bg,
        bindings = <&kp B &kp E &kp G &kp I &kp N &kp SPACE>;
    )
    // being
    ZMK_MACRO(m_beDELETE,
        bindings = <&kp B &kp E &kp I &kp N &kp G &kp SPACE>;
    )
    // below
    ZMK_MACRO(m_bel,
        bindings = <&kp B &kp E &kp L &kp O &kp W &kp SPACE>;
    )
    // dev
    ZMK_MACRO(m_dv,
        bindings = <&kp D &kp E &kp V &kp SPACE>;
    )
    // develop
    ZMK_MACRO(m_dvlp,
        bindings = <&kp D &kp E &kp V &kp E &kp L &kp O &kp P &kp SPACE>;
    )
    // between
    ZMK_MACRO(m_bew,
        bindings = <&kp B &kp E &kp T &kp W &kp E &kp E &kp N &kp SPACE>;
    )
    // big
    ZMK_MACRO(m_bi,
        bindings = <&kp B &kp I &kp G &kp SPACE>;
    )
    // book
    ZMK_MACRO(m_boSPCk,
        bindings = <&kp B &kp O &kp O &kp K &kp SPACE>;
    )
    // book
    ZMK_MACRO(m_bok,
        bindings = <&kp B &kp O &kp O &kp K &kp SPACE>;
    )
    // both
    ZMK_MACRO(m_boh,
        bindings = <&kp B &kp O &kp T &kp H &kp SPACE>;
    )
    // boy
    ZMK_MACRO(m_boy,
        bindings = <&kp B &kp O &kp Y &kp SPACE>;
    )
    // but
    ZMK_MACRO(m_bu,
        bindings = <&kp B &kp U &kp T &kp SPACE>;
    )
    // by
    ZMK_MACRO(m_by,
        bindings = <&kp B &kp Y &kp SPACE>;
    )
    // call
    ZMK_MACRO(m_cal,
        bindings = <&kp C &kp A &kp L &kp L &kp SPACE>;
    )
    // came
    ZMK_MACRO(m_cam,
        bindings = <&kp C &kp A &kp M &kp E &kp SPACE>;
    )
    // can
    ZMK_MACRO(m_can,
        bindings = <&kp C &kp A &kp N &kp SPACE>;
    )
    // car
    ZMK_MACRO(m_car,
        bindings = <&kp C &kp A &kp R &kp SPACE>;
    )
    // carry
    ZMK_MACRO(m_carSPCy,
        bindings = <&kp C &kp A &kp R &kp R &kp Y &kp SPACE>;
    )
    // carry
    ZMK_MACRO(m_cary,
        bindings = <&kp C &kp A &kp R &kp R &kp Y &kp SPACE>;
    )
    // change
    ZMK_MACRO(m_chag,
        bindings = <&kp C &kp H &kp A &kp N &kp G &kp E &kp SPACE>;
    )
    // children
    ZMK_MACRO(m_chilr,
        bindings = <&kp C &kp H &kp I &kp L &kp D &kp R &kp E &kp N &kp SPACE>;
    )
    // city
    ZMK_MACRO(m_city,
        bindings = <&kp C &kp I &kp T &kp Y &kp SPACE>;
    )
    // close
    ZMK_MACRO(m_cls,
        bindings = <&kp C &kp L &kp O &kp S &kp E &kp SPACE>;
    )
    // come
    ZMK_MACRO(m_com,
        bindings = <&kp C &kp O &kp M &kp E &kp SPACE>;
    )
    // consider
    ZMK_MACRO(m_consir,
        bindings = <&kp C &kp O &kp N &kp S &kp I &kp D &kp E &kp R &kp SPACE>;
    )
    // could
    ZMK_MACRO(m_cou,
        bindings = <&kp C &kp O &kp U &kp L &kp D &kp SPACE>;
    )
    // course
    ZMK_MACRO(m_cours,
        bindings = <&kp C &kp O &kp U &kp R &kp S &kp E &kp SPACE>;
    )
    // country
    ZMK_MACRO(m_cout,
        bindings = <&kp C &kp O &kp U &kp N &kp T &kp R &kp Y &kp SPACE>;
    )
    // cut
    ZMK_MACRO(m_cut,
        bindings = <&kp C &kp U &kp T &kp SPACE>;
    )
    // day
    ZMK_MACRO(m_day,
        bindings = <&kp D &kp A &kp Y &kp SPACE>;
    )
    // did
    ZMK_MACRO(m_di,
        bindings = <&kp D &kp I &kp D &kp SPACE>;
    )
    // did
    ZMK_MACRO(m_diSPC,
        bindings = <&kp D &kp I &kp D &kp SPACE>;
    )
    // different
    ZMK_MACRO(m_difSPC,
        bindings = <&kp D &kp I &kp F &kp F &kp E &kp R &kp E &kp N &kp T &kp SPACE>;
    )
    // do
    ZMK_MACRO(m_do,
        bindings = <&kp D &kp O &kp SPACE>;
    )
    // does
    ZMK_MACRO(m_dos,
        bindings = <&kp D &kp O &kp E &kp S &kp SPACE>;
    )
    // don't
    ZMK_MACRO(m_dont,
        bindings = <&kp D &kp O &kp N &kp SQT &kp T &kp SPACE>;
    )
    // down
    ZMK_MACRO(m_down,
        bindings = <&kp D &kp O &kp W &kp N &kp SPACE>;
    )
    // during
    ZMK_MACRO(m_durDELETE,
        bindings = <&kp D &kp U &kp R &kp I &kp N &kp G &kp SPACE>;
    )
    // each
    ZMK_MACRO(m_eah,
        bindings = <&kp E &kp A &kp C &kp H &kp SPACE>;
    )
    // early
    ZMK_MACRO(m_early,
        bindings = <&kp E &kp A &kp R &kp L &kp Y &kp SPACE>;
    )
    // earth
    ZMK_MACRO(m_earSPCh,
        bindings = <&kp E &kp A &kp R &kp T &kp H &kp SPACE>;
    )
    // eat
    ZMK_MACRO(m_eat,
        bindings = <&kp E &kp A &kp T &kp SPACE>;
    )
    // end
    ZMK_MACRO(m_en,
        bindings = <&kp E &kp N &kp D &kp SPACE>;
    )
    // enough
    ZMK_MACRO(m_enog,
        bindings = <&kp E &kp N &kp O &kp U &kp G &kp H &kp SPACE>;
    )
    // even
    ZMK_MACRO(m_evSPCn,
        bindings = <&kp E &kp V &kp E &kp N &kp SPACE>;
    )
    // even
    ZMK_MACRO(m_evn,
        bindings = <&kp E &kp V &kp E &kp N &kp SPACE>;
    )
    // every
    ZMK_MACRO(m_SPCevy,
        bindings = <&kp E &kp V &kp E &kp R &kp Y &kp SPACE>;
    )
    // example
    ZMK_MACRO(m_ex,
        bindings = <&kp E &kp X &kp A &kp M &kp P &kp L &kp E &kp SPACE>;
    )
    // example
    ZMK_MACRO(m_exampl,
        bindings = <&kp E &kp X &kp A &kp M &kp P &kp L &kp E &kp SPACE>;
    )
    // eye
    ZMK_MACRO(m_ey,
        bindings = <&kp E &kp Y &kp E &kp SPACE>;
    )
    // eye
    ZMK_MACRO(m_eySPC,
        bindings = <&kp E &kp Y &kp E &kp SPACE>;
    )
    // face
    ZMK_MACRO(m_fac,
        bindings = <&kp F &kp A &kp C &kp E &kp SPACE>;
    )
    // fact
    ZMK_MACRO(m_facSPC,
        bindings = <&kp F &kp A &kp C &kp T &kp SPACE>;
    )
    // family
    ZMK_MACRO(m_fam,
        bindings = <&kp F &kp A &kp M &kp I &kp L &kp Y &kp SPACE>;
    )
    // family
    ZMK_MACRO(m_famil,
        bindings = <&kp F &kp A &kp M &kp I &kp L &kp Y &kp SPACE>;
    )
    // far
    ZMK_MACRO(m_fa,
        bindings = <&kp F &kp A &kp R &kp SPACE>;
    )
    // father
    ZMK_MACRO(m_fahe,
        bindings = <&kp F &kp A &kp T &kp H &kp E &kp R &kp SPACE>;
    )
    // feet
    ZMK_MACRO(m_feSPC,
        bindings = <&kp F &kp E &kp E &kp T &kp SPACE>;
    )
    // feel
    ZMK_MACRO(m_feSPCl,
        bindings = <&kp F &kp E &kp E &kp L &kp SPACE>;
    )
    // fell
    ZMK_MACRO(m_felBSPC,
        bindings = <&kp F &kp E &kp L &kp L &kp SPACE>;
    )
    // few
    ZMK_MACRO(m_few,
        bindings = <&kp F &kp E &kp W &kp SPACE>;
    )
    // find
    ZMK_MACRO(m_find,
        bindings = <&kp F &kp I &kp N &kp D &kp SPACE>;
    )
    // first
    ZMK_MACRO(m_fis,
        bindings = <&kp F &kp I &kp R &kp S &kp T &kp SPACE>;
    )
    // follow
    ZMK_MACRO(m_foSPCw,
        bindings = <&kp F &kp O &kp L &kp L &kp O &kp W &kp SPACE>;
    )
    // food
    ZMK_MACRO(m_foSPCd,
        bindings = <&kp F &kp O &kp O &kp D &kp SPACE>;
    )
    // food
    ZMK_MACRO(m_fod,
        bindings = <&kp F &kp O &kp O &kp D &kp SPACE>;
    )
    // for
    ZMK_MACRO(m_foBSPC,
        bindings = <&kp F &kp O &kp R &kp SPACE>;
    )
    // form
    ZMK_MACRO(m_fom,
        bindings = <&kp F &kp O &kp R &kp M &kp SPACE>;
    )
    // found
    ZMK_MACRO(m_foud,
        bindings = <&kp F &kp O &kp U &kp N &kp D &kp SPACE>;
    )
    // four
    ZMK_MACRO(m_fouBSPC,
        bindings = <&kp F &kp O &kp U &kp R &kp SPACE>;
    )
    // from
    ZMK_MACRO(m_rom,
        bindings = <&kp F &kp R &kp O &kp M &kp SPACE>;
    )
    // get
    ZMK_MACRO(m_ge,
        bindings = <&kp G &kp E &kp T &kp SPACE>;
    )
    // general
    ZMK_MACRO(m_genal,
        bindings = <&kp G &kp E &kp N &kp E &kp R &kp A &kp L &kp SPACE>;
    )
    // girl
    ZMK_MACRO(m_girl,
        bindings = <&kp G &kp I &kp R &kp L &kp SPACE>;
    )
    // girl
    ZMK_MACRO(m_gil,
        bindings = <&kp G &kp I &kp R &kp L &kp SPACE>;
    )
    // give
    ZMK_MACRO(m_gie,
        bindings = <&kp G &kp I &kp V &kp E &kp SPACE>;
    )
    // go
    ZMK_MACRO(m_go,
        bindings = <&kp G &kp O &kp SPACE>;
    )
    // good
    ZMK_MACRO(m_goSPCd,
        bindings = <&kp G &kp O &kp O &kp D &kp SPACE>;
    )
    // got
    ZMK_MACRO(m_got,
        bindings = <&kp G &kp O &kp T &kp SPACE>;
    )
    // great
    ZMK_MACRO(m_gea,
        bindings = <&kp G &kp R &kp E &kp A &kp T &kp SPACE>;
    )
    // group
    ZMK_MACRO(m_goup,
        bindings = <&kp G &kp R &kp O &kp U &kp P &kp SPACE>;
    )
    // grow
    ZMK_MACRO(m_gow,
        bindings = <&kp G &kp R &kp O &kp W &kp SPACE>;
    )
    // had
    ZMK_MACRO(m_had,
        bindings = <&kp H &kp A &kp D &kp SPACE>;
    )
    // hand
    ZMK_MACRO(m_haSPCd,
        bindings = <&kp H &kp A &kp N &kp D &kp SPACE>;
    )
    // hard
    ZMK_MACRO(m_hard,
        bindings = <&kp H &kp A &kp R &kp D &kp SPACE>;
    )
    // has
    ZMK_MACRO(m_has,
        bindings = <&kp H &kp A &kp S &kp SPACE>;
    )
    // have
    ZMK_MACRO(m_have,
        bindings = <&kp H &kp A &kp V &kp E &kp SPACE>;
    )
    // he
    ZMK_MACRO(m_he,
        bindings = <&kp H &kp E &kp SPACE>;
    )
    // head
    ZMK_MACRO(m_heaBSPC,
        bindings = <&kp H &kp E &kp A &kp D &kp SPACE>;
    )
    // hear
    ZMK_MACRO(m_hear,
        bindings = <&kp H &kp E &kp A &kp R &kp SPACE>;
    )
    // hello
    ZMK_MACRO(m_hel,
        bindings = <&kp H &kp E &kp L &kp L &kp O &kp SPACE>;
    )
    // help
    ZMK_MACRO(m_help,
        bindings = <&kp H &kp E &kp L &kp P &kp SPACE>;
    )
    // her
    ZMK_MACRO(m_her,
        bindings = <&kp H &kp E &kp R &kp SPACE>;
    )
    // here
    ZMK_MACRO(m_herSPC,
        bindings = <&kp H &kp E &kp R &kp E &kp SPACE>;
    )
    // high
    ZMK_MACRO(m_hig,
        bindings = <&kp H &kp I &kp G &kp H &kp SPACE>;
    )
    // him
    ZMK_MACRO(m_hi,
        bindings = <&kp H &kp I &kp M &kp SPACE>;
    )
    // his
    ZMK_MACRO(m_his,
        bindings = <&kp H &kp I &kp S &kp SPACE>;
    )
    // home
    ZMK_MACRO(m_hoe,
        bindings = <&kp H &kp O &kp M &kp E &kp SPACE>;
    )
    // hold
    ZMK_MACRO(m_hod,
        bindings = <&kp H &kp O &kp L &kp D &kp SPACE>;
    )
    // house
    ZMK_MACRO(m_house,
        bindings = <&kp H &kp O &kp U &kp S &kp E &kp SPACE>;
    )
    // how
    ZMK_MACRO(m_how,
        bindings = <&kp H &kp O &kp W &kp SPACE>;
    )
    // however
    ZMK_MACRO(m_howev,
        bindings = <&kp H &kp O &kp W &kp E &kp V &kp E &kp R &kp SPACE>;
    )
    // idea
    ZMK_MACRO(m_ida,
        bindings = <&kp I &kp D &kp E &kp A &kp SPACE>;
    )
    // if
    ZMK_MACRO(m_if,
        bindings = <&kp I &kp F &kp SPACE>;
    )
    // important
    ZMK_MACRO(m_imp,
        bindings = <&kp I &kp M &kp P &kp O &kp R &kp T &kp A &kp N &kp T &kp SPACE>;
    )
    // in
    ZMK_MACRO(m_in,
        bindings = <&kp I &kp N &kp SPACE>;
    )
    // increase
    ZMK_MACRO(m_incr,
        bindings = <&kp I &kp N &kp C &kp R &kp E &kp A &kp S &kp E &kp SPACE>;
    )
    // interest
    ZMK_MACRO(m_intes,
        bindings = <&kp I &kp N &kp T &kp E &kp R &kp E &kp S &kp T &kp SPACE>;
    )
    // into
    ZMK_MACRO(m_into,
        bindings = <&kp I &kp N &kp T &kp O &kp SPACE>;
    )
    // is
    ZMK_MACRO(m_is,
        bindings = <&kp I &kp S &kp SPACE>;
    )
    // it
    ZMK_MACRO(m_it,
        bindings = <&kp I &kp T &kp SPACE>;
    )
    // it's
    ZMK_MACRO(m_itsBSPC,
        bindings = <&kp I &kp T &kp SQT &kp S &kp SPACE>;
    )
    // it_is
    ZMK_MACRO(m_itsDELETE,
        bindings = <&kp I &kp T &kp SPC &kp I &kp S &kp SPACE>;
    )
    // its
    ZMK_MACRO(m_its,
        bindings = <&kp I &kp T &kp S &kp SPACE>;
    )
    // just
    ZMK_MACRO(m_jst,
        bindings = <&kp J &kp U &kp S &kp T &kp SPACE>;
    )
    // keep
    ZMK_MACRO(m_keSPCp,
        bindings = <&kp K &kp E &kp E &kp P &kp SPACE>;
    )
    // keeping
    ZMK_MACRO(m_keSPCpDELETE,
        bindings = <&kp K &kp E &kp E &kp P &kp I &kp N &kp G &kp SPACE>;
    )
    // kind
    ZMK_MACRO(m_knd,
        bindings = <&kp K &kp I &kp N &kp D &kp SPACE>;
    )
    // know
    ZMK_MACRO(m_know,
        bindings = <&kp K &kp N &kp O &kp W &kp SPACE>;
    )
    // knowing
    ZMK_MACRO(m_knowDELETE,
        bindings = <&kp K &kp N &kp O &kp W &kp I &kp N &kp G &kp SPACE>;
    )
    // land
    ZMK_MACRO(m_land,
        bindings = <&kp L &kp A &kp N &kp D &kp SPACE>;
    )
    // landing
    ZMK_MACRO(m_landDELETE,
        bindings = <&kp L &kp A &kp N &kp D &kp I &kp N &kp G &kp SPACE>;
    )
    // large
    ZMK_MACRO(m_larg,
        bindings = <&kp L &kp A &kp R &kp G &kp E &kp SPACE>;
    )
    // last
    ZMK_MACRO(m_last,
        bindings = <&kp L &kp A &kp S &kp T &kp SPACE>;
    )
    // late
    ZMK_MACRO(m_late,
        bindings = <&kp L &kp A &kp T &kp E &kp SPACE>;
    )
    // later
    ZMK_MACRO(m_lateBSPC,
        bindings = <&kp L &kp A &kp T &kp E &kp R &kp SPACE>;
    )
    // lead
    ZMK_MACRO(m_lea,
        bindings = <&kp L &kp E &kp A &kp D &kp SPACE>;
    )
    // learn
    ZMK_MACRO(m_learn,
        bindings = <&kp L &kp E &kp A &kp R &kp N &kp SPACE>;
    )
    // learning
    ZMK_MACRO(m_learnDELETE,
        bindings = <&kp L &kp E &kp A &kp R &kp N &kp I &kp N &kp G &kp SPACE>;
    )
    // leave
    ZMK_MACRO(m_leavSPC,
        bindings = <&kp L &kp E &kp A &kp V &kp E &kp SPACE>;
    )
    // leaving
    ZMK_MACRO(m_leavDELETE,
        bindings = <&kp L &kp E &kp A &kp V &kp I &kp N &kp G &kp SPACE>;
    )
    // left
    ZMK_MACRO(m_lef,
        bindings = <&kp L &kp E &kp F &kp T &kp SPACE>;
    )
    // let
    ZMK_MACRO(m_let,
        bindings = <&kp L &kp E &kp T &kp SPACE>;
    )
    // letter
    ZMK_MACRO(m_lter,
        bindings = <&kp L &kp E &kp T &kp T &kp E &kp R &kp SPACE>;
    )
    // text
    ZMK_MACRO(m_tex,
        bindings = <&kp T &kp E &kp X &kp T &kp SPACE>;
    )
    // texting
    ZMK_MACRO(m_texDELETE,
        bindings = <&kp T &kp E &kp X &kp T &kp I &kp N &kp G &kp SPACE>;
    )
    // life
    ZMK_MACRO(m_life,
        bindings = <&kp L &kp I &kp F &kp E &kp SPACE>;
    )
    // light
    ZMK_MACRO(m_ligh,
        bindings = <&kp L &kp I &kp G &kp H &kp T &kp SPACE>;
    )
    // like
    ZMK_MACRO(m_lie,
        bindings = <&kp L &kp I &kp K &kp E &kp SPACE>;
    )
    // line
    ZMK_MACRO(m_line,
        bindings = <&kp L &kp I &kp N &kp E &kp SPACE>;
    )
    // list
    ZMK_MACRO(m_list,
        bindings = <&kp L &kp I &kp S &kp T &kp SPACE>;
    )
    // little
    ZMK_MACRO(m_lite,
        bindings = <&kp L &kp I &kp T &kp T &kp L &kp E &kp SPACE>;
    )
    // live
    ZMK_MACRO(m_live,
        bindings = <&kp L &kp I &kp V &kp E &kp SPACE>;
    )
    // long
    ZMK_MACRO(m_lng,
        bindings = <&kp L &kp O &kp N &kp G &kp SPACE>;
    )
    // look
    ZMK_MACRO(m_lSPCk,
        bindings = <&kp L &kp O &kp O &kp K &kp SPACE>;
    )
    // made
    ZMK_MACRO(m_madSPC,
        bindings = <&kp M &kp A &kp D &kp E &kp SPACE>;
    )
    // make
    ZMK_MACRO(m_make,
        bindings = <&kp M &kp A &kp K &kp E &kp SPACE>;
    )
    // man
    ZMK_MACRO(m_man,
        bindings = <&kp M &kp A &kp N &kp SPACE>;
    )
    // many
    ZMK_MACRO(m_manDELETE,
        bindings = <&kp M &kp A &kp N &kp Y &kp SPACE>;
    )
    // may
    ZMK_MACRO(m_mae,
        bindings = <&kp M &kp A &kp Y &kp SPACE>;
    )
    // me
    ZMK_MACRO(m_me,
        bindings = <&kp M &kp E &kp SPACE>;
    )
    // mean
    ZMK_MACRO(m_mean,
        bindings = <&kp M &kp E &kp A &kp N &kp SPACE>;
    )
    // men
    ZMK_MACRO(m_men,
        bindings = <&kp M &kp E &kp N &kp SPACE>;
    )
    // might
    ZMK_MACRO(m_mig,
        bindings = <&kp M &kp I &kp G &kp H &kp T &kp SPACE>;
    )
    // mile
    ZMK_MACRO(m_mile,
        bindings = <&kp M &kp I &kp L &kp E &kp SPACE>;
    )
    // miss
    ZMK_MACRO(m_misSPC,
        bindings = <&kp M &kp I &kp S &kp S &kp SPACE>;
    )
    // more
    ZMK_MACRO(m_more,
        bindings = <&kp M &kp O &kp R &kp E &kp SPACE>;
    )
    // most
    ZMK_MACRO(m_most,
        bindings = <&kp M &kp O &kp S &kp T &kp SPACE>;
    )
    // mother
    ZMK_MACRO(m_mote,
        bindings = <&kp M &kp O &kp T &kp H &kp E &kp R &kp SPACE>;
    )
    // mountain
    ZMK_MACRO(m_motaSPCDELETE,
        bindings = <&kp M &kp O &kp U &kp N &kp T &kp A &kp I &kp N &kp SPACE>;
    )
    // move
    ZMK_MACRO(m_move,
        bindings = <&kp M &kp O &kp V &kp E &kp SPACE>;
    )
    // much
    ZMK_MACRO(m_mc,
        bindings = <&kp M &kp U &kp C &kp H &kp SPACE>;
    )
    // must
    ZMK_MACRO(m_mst,
        bindings = <&kp M &kp U &kp S &kp T &kp SPACE>;
    )
    // my
    ZMK_MACRO(m_mDELETE,
        bindings = <&kp M &kp Y &kp SPACE>;
    )
    // name
    ZMK_MACRO(m_nae,
        bindings = <&kp N &kp A &kp M &kp E &kp SPACE>;
    )
    // nation
    ZMK_MACRO(m_natio,
        bindings = <&kp N &kp A &kp T &kp I &kp O &kp N &kp SPACE>;
    )
    // near
    ZMK_MACRO(m_near,
        bindings = <&kp N &kp E &kp A &kp R &kp SPACE>;
    )
    // need
    ZMK_MACRO(m_neSPC,
        bindings = <&kp N &kp E &kp E &kp D &kp SPACE>;
    )
    // never
    ZMK_MACRO(m_nevBSPC,
        bindings = <&kp N &kp E &kp V &kp E &kp R &kp SPACE>;
    )
    // new
    ZMK_MACRO(m_new,
        bindings = <&kp N &kp E &kp W &kp SPACE>;
    )
    // next
    ZMK_MACRO(m_next,
        bindings = <&kp N &kp E &kp X &kp T &kp SPACE>;
    )
    // night
    ZMK_MACRO(m_nig,
        bindings = <&kp N &kp I &kp G &kp H &kp T &kp SPACE>;
    )
    // no
    ZMK_MACRO(m_nSPC,
        bindings = <&kp N &kp O &kp SPACE>;
    )
    // not
    ZMK_MACRO(m_not,
        bindings = <&kp N &kp O &kp T &kp SPACE>;
    )
    // now
    ZMK_MACRO(m_nSPCw,
        bindings = <&kp N &kp O &kp W &kp SPACE>;
    )
    // number
    ZMK_MACRO(m_nmb,
        bindings = <&kp N &kp U &kp M &kp B &kp E &kp R &kp SPACE>;
    )
    // off
    ZMK_MACRO(m_ofSPC,
        bindings = <&kp O &kp F &kp F &kp SPACE>;
    )
    // of
    ZMK_MACRO(m_of,
        bindings = <&kp O &kp F &kp SPACE>;
    )
    // often
    ZMK_MACRO(m_ofe,
        bindings = <&kp O &kp F &kp T &kp E &kp N &kp SPACE>;
    )
    // old
    ZMK_MACRO(m_oSPCd,
        bindings = <&kp O &kp L &kp D &kp SPACE>;
    )
    // on
    ZMK_MACRO(m_on,
        bindings = <&kp O &kp N &kp SPACE>;
    )
    // once
    ZMK_MACRO(m_onc,
        bindings = <&kp O &kp N &kp C &kp E &kp SPACE>;
    )
    // one
    ZMK_MACRO(m_one,
        bindings = <&kp O &kp N &kp E &kp SPACE>;
    )
    // only
    ZMK_MACRO(m_onDELETE,
        bindings = <&kp O &kp N &kp L &kp Y &kp SPACE>;
    )
    // open
    ZMK_MACRO(m_open,
        bindings = <&kp O &kp P &kp E &kp N &kp SPACE>;
    )
    // or
    ZMK_MACRO(m_or,
        bindings = <&kp O &kp R &kp SPACE>;
    )
    // order
    ZMK_MACRO(m_ordSPC,
        bindings = <&kp O &kp R &kp D &kp E &kp R &kp SPACE>;
    )
    // other
    ZMK_MACRO(m_othe,
        bindings = <&kp O &kp T &kp H &kp E &kp R &kp SPACE>;
    )
    // our
    ZMK_MACRO(m_our,
        bindings = <&kp O &kp U &kp R &kp SPACE>;
    )
    // out
    ZMK_MACRO(m_out,
        bindings = <&kp O &kp U &kp T &kp SPACE>;
    )
    // over
    ZMK_MACRO(m_ove,
        bindings = <&kp O &kp V &kp E &kp R &kp SPACE>;
    )
    // own
    ZMK_MACRO(m_own,
        bindings = <&kp O &kp W &kp N &kp SPACE>;
    )
    // page
    ZMK_MACRO(m_page,
        bindings = <&kp P &kp A &kp G &kp E &kp SPACE>;
    )
    // paper
    ZMK_MACRO(m_paer,
        bindings = <&kp P &kp A &kp P &kp E &kp R &kp SPACE>;
    )
    // part
    ZMK_MACRO(m_par,
        bindings = <&kp P &kp A &kp R &kp T &kp SPACE>;
    )
    // people
    ZMK_MACRO(m_peoSPC,
        bindings = <&kp P &kp E &kp O &kp P &kp L &kp E &kp SPACE>;
    )
    // person
    ZMK_MACRO(m_pers,
        bindings = <&kp P &kp E &kp R &kp S &kp O &kp N &kp SPACE>;
    )
    // picture
    ZMK_MACRO(m_pict,
        bindings = <&kp P &kp I &kp C &kp T &kp U &kp R &kp E &kp SPACE>;
    )
    // place
    ZMK_MACRO(m_plac,
        bindings = <&kp P &kp L &kp A &kp C &kp E &kp SPACE>;
    )
    // plant
    ZMK_MACRO(m_plan,
        bindings = <&kp P &kp L &kp A &kp N &kp T &kp SPACE>;
    )
    // plant
    ZMK_MACRO(m_plant,
        bindings = <&kp P &kp L &kp A &kp N &kp T &kp SPACE>;
    )
    // play
    ZMK_MACRO(m_play,
        bindings = <&kp P &kp L &kp A &kp Y &kp SPACE>;
    )
    // problem
    ZMK_MACRO(m_proem,
        bindings = <&kp P &kp R &kp O &kp B &kp L &kp E &kp M &kp SPACE>;
    )
    // program
    ZMK_MACRO(m_proam,
        bindings = <&kp P &kp R &kp O &kp G &kp R &kp A &kp M &kp SPACE>;
    )
    // present
    ZMK_MACRO(m_presn,
        bindings = <&kp P &kp R &kp E &kp S &kp E &kp N &kp T &kp SPACE>;
    )
    // point
    ZMK_MACRO(m_point,
        bindings = <&kp P &kp O &kp I &kp N &kp T &kp SPACE>;
    )
    // position
    ZMK_MACRO(m_pos,
        bindings = <&kp P &kp O &kp S &kp I &kp T &kp I &kp O &kp N &kp SPACE>;
    )
    // possible
    ZMK_MACRO(m_posib,
        bindings = <&kp P &kp O &kp S &kp S &kp I &kp B &kp L &kp E &kp SPACE>;
    )
    // put
    ZMK_MACRO(m_put,
        bindings = <&kp P &kp U &kp T &kp SPACE>;
    )
    // public
    ZMK_MACRO(m_pubic,
        bindings = <&kp P &kp U &kp B &kp L &kp I &kp C &kp SPACE>;
    )
    // question
    ZMK_MACRO(m_quet,
        bindings = <&kp Q &kp U &kp E &kp S &kp T &kp I &kp O &kp N &kp SPACE>;
    )
    // quick
    ZMK_MACRO(m_qui,
        bindings = <&kp Q &kp U &kp I &kp C &kp K &kp SPACE>;
    )
    // quickly
    ZMK_MACRO(m_quiDELETE,
        bindings = <&kp Q &kp U &kp I &kp C &kp K &kp L &kp Y &kp SPACE>;
    )
    // quite
    ZMK_MACRO(m_quite,
        bindings = <&kp Q &kp U &kp I &kp T &kp E &kp SPACE>;
    )
    // read
    ZMK_MACRO(m_reaBSPC,
        bindings = <&kp R &kp E &kp A &kp D &kp SPACE>;
    )
    // real
    ZMK_MACRO(m_real,
        bindings = <&kp R &kp E &kp A &kp L &kp SPACE>;
    )
    // really
    ZMK_MACRO(m_realDELETE,
        bindings = <&kp R &kp E &kp A &kp L &kp L &kp Y &kp SPACE>;
    )
    // right
    ZMK_MACRO(m_righ,
        bindings = <&kp R &kp I &kp G &kp H &kp T &kp SPACE>;
    )
    // river
    ZMK_MACRO(m_rie,
        bindings = <&kp R &kp I &kp V &kp E &kp R &kp SPACE>;
    )
    // run
    ZMK_MACRO(m_ru,
        bindings = <&kp R &kp U &kp N &kp SPACE>;
    )
    // said
    ZMK_MACRO(m_said,
        bindings = <&kp S &kp A &kp I &kp D &kp SPACE>;
    )
    // same
    ZMK_MACRO(m_same,
        bindings = <&kp S &kp A &kp M &kp E &kp SPACE>;
    )
    // saw
    ZMK_MACRO(m_saBSPC,
        bindings = <&kp S &kp A &kp W &kp SPACE>;
    )
    // say
    ZMK_MACRO(m_say,
        bindings = <&kp S &kp A &kp Y &kp SPACE>;
    )
    // school
    ZMK_MACRO(m_scho,
        bindings = <&kp S &kp C &kp H &kp O &kp O &kp L &kp SPACE>;
    )
    // sea
    ZMK_MACRO(m_sea,
        bindings = <&kp S &kp E &kp A &kp SPACE>;
    )
    // second
    ZMK_MACRO(m_seon,
        bindings = <&kp S &kp E &kp C &kp O &kp N &kp D &kp SPACE>;
    )
    // see
    ZMK_MACRO(m_seSPC,
        bindings = <&kp S &kp E &kp E &kp SPACE>;
    )
    // seem
    ZMK_MACRO(m_seSPCm,
        bindings = <&kp S &kp E &kp E &kp M &kp SPACE>;
    )
    // sentence
    ZMK_MACRO(m_sent,
        bindings = <&kp S &kp E &kp N &kp T &kp E &kp N &kp C &kp E &kp SPACE>;
    )
    // set
    ZMK_MACRO(m_set,
        bindings = <&kp S &kp E &kp T &kp SPACE>;
    )
    // she
    ZMK_MACRO(m_she,
        bindings = <&kp S &kp H &kp E &kp SPACE>;
    )
    // should
    ZMK_MACRO(m_shoSPCd,
        bindings = <&kp S &kp H &kp O &kp U &kp L &kp D &kp SPACE>;
    )
    // show
    ZMK_MACRO(m_sho,
        bindings = <&kp S &kp H &kp O &kp W &kp SPACE>;
    )
    // side
    ZMK_MACRO(m_sid,
        bindings = <&kp S &kp I &kp D &kp E &kp SPACE>;
    )
    // since
    ZMK_MACRO(m_sinc,
        bindings = <&kp S &kp I &kp N &kp C &kp E &kp SPACE>;
    )
    // small
    ZMK_MACRO(m_smal,
        bindings = <&kp S &kp M &kp A &kp L &kp L &kp SPACE>;
    )
    // so
    ZMK_MACRO(m_so,
        bindings = <&kp S &kp O &kp SPACE>;
    )
    // some
    ZMK_MACRO(m_some,
        bindings = <&kp S &kp O &kp M &kp E &kp SPACE>;
    )
    // something
    ZMK_MACRO(m_somet,
        bindings = <&kp S &kp O &kp M &kp E &kp T &kp H &kp I &kp N &kp G &kp SPACE>;
    )
    // sometimes
    ZMK_MACRO(m_sometSPC,
        bindings = <&kp S &kp O &kp M &kp E &kp T &kp I &kp M &kp E &kp S &kp SPACE>;
    )
    // song
    ZMK_MACRO(m_song,
        bindings = <&kp S &kp O &kp N &kp G &kp SPACE>;
    )
    // soon
    ZMK_MACRO(m_soSPCn,
        bindings = <&kp S &kp O &kp O &kp N &kp SPACE>;
    )
    // sound
    ZMK_MACRO(m_soud,
        bindings = <&kp S &kp O &kp U &kp N &kp D &kp SPACE>;
    )
    // spell
    ZMK_MACRO(m_spel,
        bindings = <&kp S &kp P &kp E &kp L &kp L &kp SPACE>;
    )
    // speed
    ZMK_MACRO(m_speSPC,
        bindings = <&kp S &kp P &kp E &kp E &kp D &kp SPACE>;
    )
    // start
    ZMK_MACRO(m_star,
        bindings = <&kp S &kp T &kp A &kp R &kp T &kp SPACE>;
    )
    // state
    ZMK_MACRO(m_stae,
        bindings = <&kp S &kp T &kp A &kp T &kp E &kp SPACE>;
    )
    // still
    ZMK_MACRO(m_stilSPC,
        bindings = <&kp S &kp T &kp I &kp L &kp L &kp SPACE>;
    )
    // stop
    ZMK_MACRO(m_stop,
        bindings = <&kp S &kp T &kp O &kp P &kp SPACE>;
    )
    // story
    ZMK_MACRO(m_stoy,
        bindings = <&kp S &kp T &kp O &kp R &kp Y &kp SPACE>;
    )
    // study
    ZMK_MACRO(m_stud,
        bindings = <&kp S &kp T &kp U &kp D &kp Y &kp SPACE>;
    )
    // such
    ZMK_MACRO(m_suc,
        bindings = <&kp S &kp U &kp C &kp H &kp SPACE>;
    )
    // system
    ZMK_MACRO(m_syte,
        bindings = <&kp S &kp Y &kp S &kp T &kp E &kp M &kp SPACE>;
    )
    // take
    ZMK_MACRO(m_take,
        bindings = <&kp T &kp A &kp K &kp E &kp SPACE>;
    )
    // talk
    ZMK_MACRO(m_talk,
        bindings = <&kp T &kp A &kp L &kp K &kp SPACE>;
    )
    // tell
    ZMK_MACRO(m_telSPC,
        bindings = <&kp T &kp E &kp L &kp L &kp SPACE>;
    )
    // than
    ZMK_MACRO(m_thaDELETE,
        bindings = <&kp T &kp H &kp A &kp N &kp SPACE>;
    )
    // that
    ZMK_MACRO(m_tha,
        bindings = <&kp T &kp H &kp A &kp T &kp SPACE>;
    )
    // their
    ZMK_MACRO(m_thei,
        bindings = <&kp T &kp H &kp E &kp I &kp R &kp SPACE>;
    )
    // them
    ZMK_MACRO(m_the,
        bindings = <&kp T &kp H &kp E &kp M &kp SPACE>;
    )
    // then
    ZMK_MACRO(m_theBSPC,
        bindings = <&kp T &kp H &kp E &kp N &kp SPACE>;
    )
    // there
    ZMK_MACRO(m_ther,
        bindings = <&kp T &kp H &kp E &kp R &kp E &kp SPACE>;
    )
    // these
    ZMK_MACRO(m_thes,
        bindings = <&kp T &kp H &kp E &kp S &kp E &kp SPACE>;
    )
    // the
    ZMK_MACRO(m_th,
        bindings = <&kp T &kp H &kp E &kp SPACE>;
    )
    // they
    ZMK_MACRO(m_theSPC,
        bindings = <&kp T &kp H &kp E &kp Y &kp SPACE>;
    )
    // thing
    ZMK_MACRO(m_thiDELETE,
        bindings = <&kp T &kp H &kp I &kp N &kp G &kp SPACE>;
    )
    // think
    ZMK_MACRO(m_thi,
        bindings = <&kp T &kp H &kp I &kp N &kp K &kp SPACE>;
    )
    // this
    ZMK_MACRO(m_this,
        bindings = <&kp T &kp H &kp I &kp S &kp SPACE>;
    )
    // those
    ZMK_MACRO(m_those,
        bindings = <&kp T &kp H &kp O &kp S &kp E &kp SPACE>;
    )
    // thought
    ZMK_MACRO(m_touBSPC,
        bindings = <&kp T &kp H &kp O &kp U &kp G &kp H &kp T &kp SPACE>;
    )
    // three
    ZMK_MACRO(m_threSPC,
        bindings = <&kp T &kp H &kp R &kp E &kp E &kp SPACE>;
    )
    // through
    ZMK_MACRO(m_thro,
        bindings = <&kp T &kp H &kp R &kp O &kp U &kp G &kp H &kp SPACE>;
    )
    // time
    ZMK_MACRO(m_time,
        bindings = <&kp T &kp I &kp M &kp E &kp SPACE>;
    )
    // type
    ZMK_MACRO(m_type,
        bindings = <&kp T &kp Y &kp P &kp E &kp SPACE>;
    )
    // typed
    ZMK_MACRO(m_typeBSPC,
        bindings = <&kp T &kp Y &kp P &kp E &kp D &kp SPACE>;
    )
    // typing
    ZMK_MACRO(m_typeDELETE,
        bindings = <&kp T &kp Y &kp P &kp I &kp N &kp G &kp SPACE>;
    )
    // together
    ZMK_MACRO(m_toehSPC,
        bindings = <&kp T &kp O &kp G &kp E &kp T &kp H &kp E &kp R &kp SPACE>;
    )
    // too
    ZMK_MACRO(m_toSPC,
        bindings = <&kp T &kp O &kp O &kp SPACE>;
    )
    // took
    ZMK_MACRO(m_toSPCk,
        bindings = <&kp T &kp O &kp O &kp K &kp SPACE>;
    )
    // to
    ZMK_MACRO(m_to,
        bindings = <&kp T &kp O &kp SPACE>;
    )
    // tree
    ZMK_MACRO(m_tre,
        bindings = <&kp T &kp R &kp E &kp E &kp SPACE>;
    )
    // try
    ZMK_MACRO(m_try,
        bindings = <&kp T &kp R &kp Y &kp SPACE>;
    )
    // turn
    ZMK_MACRO(m_tur,
        bindings = <&kp T &kp U &kp R &kp N &kp SPACE>;
    )
    // two
    ZMK_MACRO(m_two,
        bindings = <&kp T &kp W &kp O &kp SPACE>;
    )
    // under
    ZMK_MACRO(m_undr,
        bindings = <&kp U &kp N &kp D &kp E &kp R &kp SPACE>;
    )
    // until
    ZMK_MACRO(m_uSPCtil,
        bindings = <&kp U &kp N &kp T &kp I &kp L &kp SPACE>;
    )
    // up
    ZMK_MACRO(m_up,
        bindings = <&kp U &kp P &kp SPACE>;
    )
    // us
    ZMK_MACRO(m_us,
        bindings = <&kp U &kp S &kp SPACE>;
    )
    // use
    ZMK_MACRO(m_use,
        bindings = <&kp U &kp S &kp E &kp SPACE>;
    )
    // very
    ZMK_MACRO(m_vey,
        bindings = <&kp V &kp E &kp R &kp Y &kp SPACE>;
    )
    // walk
    ZMK_MACRO(m_walk,
        bindings = <&kp W &kp A &kp L &kp K &kp SPACE>;
    )
    // want
    ZMK_MACRO(m_want,
        bindings = <&kp W &kp A &kp N &kp T &kp SPACE>;
    )
    // was
    ZMK_MACRO(m_waBSPC,
        bindings = <&kp W &kp A &kp S &kp SPACE>;
    )
    // watch
    ZMK_MACRO(m_waBSPCth,
        bindings = <&kp W &kp A &kp T &kp C &kp H &kp SPACE>;
    )
    // water
    ZMK_MACRO(m_wate,
        bindings = <&kp W &kp A &kp T &kp E &kp R &kp SPACE>;
    )
    // way
    ZMK_MACRO(m_way,
        bindings = <&kp W &kp A &kp Y &kp SPACE>;
    )
    // we
    ZMK_MACRO(m_we,
        bindings = <&kp W &kp E &kp SPACE>;
    )
    // well
    ZMK_MACRO(m_wel,
        bindings = <&kp W &kp E &kp L &kp L &kp SPACE>;
    )
    // went
    ZMK_MACRO(m_went,
        bindings = <&kp W &kp E &kp N &kp T &kp SPACE>;
    )
    // were
    ZMK_MACRO(m_werSPC,
        bindings = <&kp W &kp E &kp R &kp E &kp SPACE>;
    )
    // what
    ZMK_MACRO(m_what,
        bindings = <&kp W &kp H &kp A &kp T &kp SPACE>;
    )
    // when
    ZMK_MACRO(m_wheSPC,
        bindings = <&kp W &kp H &kp E &kp N &kp SPACE>;
    )
    // where
    ZMK_MACRO(m_wherSPC,
        bindings = <&kp W &kp H &kp E &kp R &kp E &kp SPACE>;
    )
    // which
    ZMK_MACRO(m_whic,
        bindings = <&kp W &kp H &kp I &kp C &kp H &kp SPACE>;
    )
    // while
    ZMK_MACRO(m_while,
        bindings = <&kp W &kp H &kp I &kp L &kp E &kp SPACE>;
    )
    // white
    ZMK_MACRO(m_white,
        bindings = <&kp W &kp H &kp I &kp T &kp E &kp SPACE>;
    )
    // who
    ZMK_MACRO(m_whoBSPC,
        bindings = <&kp W &kp H &kp O &kp SPACE>;
    )
    // why
    ZMK_MACRO(m_whDELETE,
        bindings = <&kp W &kp H &kp Y &kp SPACE>;
    )
    // will
    ZMK_MACRO(m_wil,
        bindings = <&kp W &kp I &kp L &kp L &kp SPACE>;
    )
    // with
    ZMK_MACRO(m_with,
        bindings = <&kp W &kp I &kp T &kp H &kp SPACE>;
    )
    // without
    ZMK_MACRO(m_witho,
        bindings = <&kp W &kp I &kp T &kp H &kp O &kp U &kp T &kp SPACE>;
    )
    // word
    ZMK_MACRO(m_word,
        bindings = <&kp W &kp O &kp R &kp D &kp SPACE>;
    )
    // work
    ZMK_MACRO(m_work,
        bindings = <&kp W &kp O &kp R &kp K &kp SPACE>;
    )
    // world
    ZMK_MACRO(m_worSPCd,
        bindings = <&kp W &kp O &kp R &kp L &kp D &kp SPACE>;
    )
    // would
    ZMK_MACRO(m_woud,
        bindings = <&kp W &kp O &kp U &kp L &kp D &kp SPACE>;
    )
    // write
    ZMK_MACRO(m_wrie,
        bindings = <&kp W &kp R &kp I &kp T &kp E &kp SPACE>;
    )
    // year
    ZMK_MACRO(m_year,
        bindings = <&kp Y &kp E &kp A &kp R &kp SPACE>;
    )
    // you
    ZMK_MACRO(m_you,
        bindings = <&kp Y &kp O &kp U &kp SPACE>;
    )
    // young
    ZMK_MACRO(m_youg,
        bindings = <&kp Y &kp O &kp U &kp N &kp G &kp SPACE>;
    )
    // your
    ZMK_MACRO(m_your,
        bindings = <&kp Y &kp O &kp U &kp R &kp SPACE>;
    )

        // MACROS END
    };

    keymap {
        compatible = "zmk,keymap";

        default_layer {
            display-name = "Base";
            bindings = <
&kp EQUAL  &kp N1     &kp N2      &kp N3    &kp N4     &kp N5  &tog 1                                                   &mo 3      &kp N6  &kp N7    &kp N8     &kp N9    &kp N0    &kp MINUS
&kp TAB    &kp Q      &kp W       &kp E     &kp R      &kp T   &none                                                    &none      &kp Y   &kp U     &kp I      &kp O     &kp P     &kp BSLH
&kp ESC    &kp A      &kp S       &kp D     &kp F      &kp G   &none     &kp LCTRL  &kp LALT      &kp LGUI   &kp RCTRL  &none      &kp H   &kp J     &kp K      &kp L     &kp SEMI  &kp SQT
&kp LSHFT  &kp Z      &kp X       &kp C     &kp V      &kp B                        &kp HOME      &kp PG_UP                        &kp N   &kp M     &kp COMMA  &kp DOT   &kp FSLH  &kp RSHFT
&mo 2      &kp GRAVE  &caps_word  &kp LEFT  &kp RIGHT          &kp BSPC  &kp DEL    &kp END       &kp PG_DN  &kp ENTER  &kp SPACE          &kp DOWN  &kp UP     &kp LBKT  &kp RBKT  &mo 2
            >;
        };

        keypad {
            display-name = "Kp";
            bindings = <
&kp EQUAL  &kp N1     &kp N2      &kp N3    &kp N4     &kp N5  &trans                                                   &mo 3      &kp N6  &kp KP_NUM  &kp KP_EQUAL  &kp KP_DIVIDE  &kp KP_MULTIPLY  &kp MINUS
&kp TAB    &kp Q      &kp W       &kp E     &kp R      &kp T   &none                                                    &none      &kp Y   &kp KP_N7   &kp KP_N8     &kp KP_N9      &kp KP_MINUS     &kp BSLH
&kp ESC    &kp A      &kp S       &kp D     &kp F      &kp G   &none     &kp LCTRL  &kp LALT      &kp LGUI   &kp RCTRL  &none      &kp H   &kp KP_N4   &kp KP_N5     &kp KP_N6      &kp KP_PLUS      &kp SQT
&kp LSHFT  &kp Z      &kp X       &kp C     &kp V      &kp B                        &kp HOME      &kp PG_UP                        &kp N   &kp KP_N1   &kp KP_N2     &kp KP_N3      &kp KP_ENTER     &kp RSHFT
&mo 2      &kp GRAVE  &caps_word  &kp LEFT  &kp RIGHT          &kp BSPC  &kp DEL    &kp END       &kp PG_DN  &kp ENTER  &kp KP_N0          &kp DOWN    &kp UP        &kp KP_DOT     &kp RBKT         &mo 2
            >;
        };

        fn {
            display-name = "Fn";
            bindings = <
&kp F1  &kp F2  &kp F3  &kp F4  &kp F5  &kp F6  &tog 1                                      &mo 3   &kp F7  &kp F8        &kp F9        &kp F10  &kp F11  &kp F12
&trans  &trans  &trans  &trans  &trans  &trans  &none                                       &none   &trans  &trans        &trans        &trans   &trans   &trans
&trans  &trans  &trans  &trans  &trans  &trans  &none   &trans  &trans      &trans  &trans  &none   &trans  &kp C_VOL_DN  &kp C_VOL_UP  &trans   &trans   &trans
&trans  &trans  &trans  &trans  &trans  &trans                  &trans      &trans                  &trans  &trans        &trans        &trans   &trans   &trans
&trans  &trans  &trans  &trans  &trans          &trans  &trans  &trans      &trans  &trans  &trans          &trans        &trans        &trans   &trans   &trans
            >;
        };

        mod {
            display-name = "Mod";
            bindings = <
&none           &bt BT_SEL 0  &bt BT_SEL 1  &bt BT_SEL 2  &bt BT_SEL 3  &bt BT_SEL 4  &none                                                  &trans           &none  &none       &none       &none  &none  &none
&none           &none         &none         &none         &none         &none         &bootloader                                            &bootloader      &none  &none       &none       &none  &none  &none
&studio_unlock  &none         &none         &none         &none         &none         &none        &none  &none      &bt BT_CLR  &none       &stp STP_BAT     &none  &none       &none       &none  &none  &none
&none           &none         &none         &none         &macro_ver    &none                             &none      &none                                    &none  &none       &none       &none  &none  &none
&none           &none         &none         &none         &none                       &none        &none  &none      &none       &bl BL_TOG  &rgb_ug RGB_TOG         &bl BL_INC  &bl BL_DEC  &none  &none  &none
            >;
        };

        extra1 {
            display-name = "Red";
            status = "reserved";
        };

        extra2 {
            display-name = "Purple";
            status = "reserved";
        };

        extra3 {
            display-name = "Cyan";
            status = "reserved";
        };

        extra4 {
            display-name = "Yellow";
            status = "reserved";
        };
    };
};
